VERSION ""

NS_ :

BS_:

BU_: LDCMC LDCMD LDCMF LDCME CSDB CSDA HCM TSTR LDCMA LDCMB

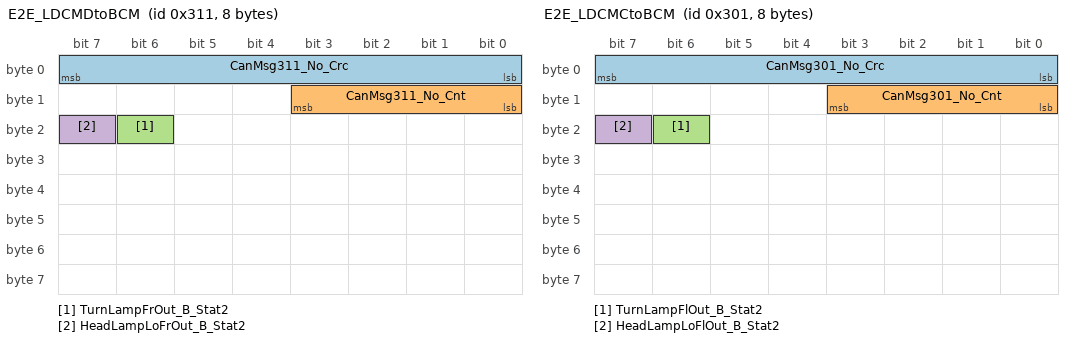
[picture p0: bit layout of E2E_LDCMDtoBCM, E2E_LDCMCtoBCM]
BO_ 785 E2E_LDCMDtoBCM: 8 LDCMD
 SG_ CanMsg311_No_Crc : 7|8@0+ (1,0) [0|255] "Unitless"  HCM
 SG_ CanMsg311_No_Cnt : 11|4@0+ (1,0) [0|15] "Unitless"  HCM
 SG_ TurnLampFrOut_B_Stat2 : 22|1@0+ (1,0) [0|1] ""  HCM
 SG_ HeadLampLoFrOut_B_Stat2 : 23|1@0+ (1,0) [0|1] "SED"  HCM

BO_ 769 E2E_LDCMCtoBCM: 8 LDCMC
 SG_ CanMsg301_No_Crc : 7|8@0+ (1,0) [0|255] "Unitless"  HCM
 SG_ CanMsg301_No_Cnt : 11|4@0+ (1,0) [0|15] "Unitless"  HCM
 SG_ TurnLampFlOut_B_Stat2 : 22|1@0+ (1,0) [0|1] ""  HCM
 SG_ HeadLampLoFlOut_B_Stat2 : 23|1@0+ (1,0) [0|1] "SED"  HCM

BO_ 125 HlStatFR2: 7 LDCMD
 SG_ LDM_HbFdbckRght_B_Stat2 : 10|1@0+ (1,0) [0|1] ""  HCM
 SG_ HlLoFrOnfdbck_B_Stat2 : 8|1@0+ (1,0) [0|1] "SED"  HCM
 SG_ Hlr_Temp_Stat2 : 4|1@0+ (1,0) [0|1] ""  HCM
 SG_ Mdule2RightHl_side_Stat : 3|2@0+ (1,0) [0|3] ""  HCM
 SG_ Mdule2RightHl_Com_Stat : 5|1@0+ (1,0) [0|1] ""  HCM
 SG_ Mdule2Right_MPwr_B_Stat : 6|1@0+ (1,0) [0|1] ""  HCM
 SG_ Mdule2Right_LB_Pwr_B_Stat : 7|1@0+ (1,0) [0|1] ""  HCM
 SG_ Hlr_SM_Stat2 : 13|1@0+ (1,0) [0|1] ""  HCM
 SG_ Hlr_SBL_Stat2 : 14|1@0+ (1,0) [0|1] ""  HCM
 SG_ Hlr_Pixel_Stat2 : 12|1@0+ (1,0) [0|1] ""  HCM
 SG_ Hlr_Fan_B_Stat2 : 15|1@0+ (1,0) [0|1] ""  HCM
 SG_ Hlr_DRL_POS_Stat2 : 11|1@0+ (1,0) [0|1] ""  HCM
 SG_ Hlr_LvlMotor_Temp_Stat2 : 23|2@0+ (1,0) [0|3] ""  HCM
 SG_ HeadLghtLvlRght_D_Stat2 : 21|3@0+ (1,0) [0|7] ""  HCM
 SG_ HeadLghtLvlRght_No_Stat2 : 29|12@0+ (1,0) [0|4095] "1/2 step"  HCM
 SG_ Mdule2RightFail_B_Stat : 1|1@0+ (1,0) [0|1] ""  HCM
 SG_ Mdule2RightConfg_B_Stat : 0|1@0+ (1,0) [0|1] ""  HCM

BO_ 124 HlStatFL2: 8 LDCMC
 SG_ LDM_HbFdbckLeft_B_Stat2 : 10|1@0+ (1,0) [0|1] ""  HCM
 SG_ HlLoFlOnfdbck_B_Stat2 : 8|1@0+ (1,0) [0|1] "SED"  HCM
 SG_ HeadLghtLvlLeft_No_Stat2 : 29|12@0+ (1,0) [0|4095] "1/2 step"  HCM
 SG_ Hll_Temp_Stat2 : 4|1@0+ (1,0) [0|1] ""  HCM
 SG_ Mdule2LeftHl_side_Stat : 3|2@0+ (1,0) [0|3] ""  HCM
 SG_ Mdule2LeftHl_Com_Stat : 5|1@0+ (1,0) [0|1] ""  HCM
 SG_ Mdule2Left_MPwr_B_Stat : 6|1@0+ (1,0) [0|1] ""  HCM
 SG_ Mdule2Left_LB_Pwr_B_Stat : 7|1@0+ (1,0) [0|1] ""  HCM
 SG_ Hll_SM_Stat2 : 13|1@0+ (1,0) [0|1] ""  HCM
 SG_ Hll_SBL_Stat2 : 14|1@0+ (1,0) [0|1] ""  HCM
 SG_ Hll_Pixel_Stat2 : 12|1@0+ (1,0) [0|1] ""  HCM
 SG_ Hll_Fan_B_Stat2 : 15|1@0+ (1,0) [0|1] ""  HCM
 SG_ Hll_DRL_POS_Stat2 : 11|1@0+ (1,0) [0|1] ""  HCM
 SG_ Hll_LvlMotor_Temp_Stat2 : 23|2@0+ (1,0) [0|3] ""  HCM
 SG_ HeadLghtLvlLeft_D_Stat2 : 21|3@0+ (1,0) [0|7] ""  HCM
 SG_ Mdule2LeftFail_B_Stat : 1|1@0+ (1,0) [0|1] ""  HCM
 SG_ Mdule2LeftConfg_B_Stat : 0|1@0+ (1,0) [0|1] ""  HCM

BO_ 1555 XCP_TSTRtoLDCMD: 64 TSTR
 SG_ XCP_TSTRtoLDCMD : 7|64@0+ (1,0) [0|1.84467E+019] "unitless"  LDCMD

BO_ 1554 XCP_TSTRtoLDCMC: 64 TSTR
 SG_ XCP_TSTRtoLDCMC : 7|64@0+ (1,0) [0|1.84467E+019] "unitless"  LDCMC

BO_ 1539 XCP_LDCMDtoTSTR: 64 LDCMD
 SG_ XCP_LDCMDtoTSTR : 7|64@0+ (1,0) [0|1.84467E+019] "unitless"  TSTR

BO_ 1538 XCP_LDCMCtoTSTR: 64 LDCMC
 SG_ XCP_LDCMCtoTSTR : 7|64@0+ (1,0) [0|1.84467E+019] "unitless"  TSTR

BO_ 2612224122 PARSEDPushLDCMDtoGWM_ECG: 64 LDCMD
 SG_ PARSEDPushLDCMDtoGWM_ECG : 7|29@0+ (1,0) [0|536870911] "unitless"  HCM

BO_ 2612224125 PARSEDPushLDCMCtoGWM_ECG: 64 LDCMC
 SG_ PARSEDPushLDCMCtoGWM_ECG : 7|29@0+ (1,0) [0|536870911] "unitless"  HCM

BO_ 2612127960 PARSEDPushFcGWM_ECGtoLDCMD: 64 HCM
 SG_ PARSEDPushFcGWM_ECGtoLDCMD : 7|29@0+ (1,0) [0|536870911] "unitless"  LDCMD

BO_ 2612131032 PARSEDPushFcGWM_ECGtoLDCMC: 64 HCM
 SG_ PARSEDPushFcGWM_ECGtoLDCMC : 7|29@0+ (1,0) [0|536870911] "unitless"  LDCMC

BO_ 2611175546 PARSEDPhysLDCMDtoGWM_ECG: 64 LDCMD
 SG_ PARSEDPhysLDCMDtoGWM_ECG : 7|29@0+ (1,0) [0|536870911] "unitless"  HCM

BO_ 2611175549 PARSEDPhysLDCMCtoGWM_ECG: 64 LDCMC
 SG_ PARSEDPhysLDCMCtoGWM_ECG : 7|29@0+ (1,0) [0|536870911] "unitless"  HCM

BO_ 2611079384 PARSEDPhysGWM_ECGtoLDCMD: 64 HCM
 SG_ PARSEDPhysGWM_ECGtoLDCMD : 7|29@0+ (1,0) [0|536870911] "unitless"  LDCMD

BO_ 2611082456 PARSEDPhysGWM_ECGtoLDCMC: 64 HCM
 SG_ PARSEDPhysGWM_ECGtoLDCMC : 7|29@0+ (1,0) [0|536870911] "unitless"  LDCMC

BO_ 2610126970 OTAPhysLDCMDtoGWM_ECG: 64 LDCMD
 SG_ OTAPhysLDCMDtoGWM_ECG : 7|29@0+ (1,0) [0|536870911] "unitless"  HCM

BO_ 2610126973 OTAPhysLDCMCtoGWM_ECG: 64 LDCMC
 SG_ OTAPhysLDCMCtoGWM_ECG : 7|29@0+ (1,0) [0|536870911] "unitless"  HCM

BO_ 2610030808 OTAPhysGWM_ECGtoLDCMD: 64 HCM
 SG_ OTAPhysGWM_ECGtoLDCMD : 7|29@0+ (1,0) [0|536870911] "unitless"  LDCMD

BO_ 2610033880 OTAPhysGWM_ECGtoLDCMC: 64 HCM
 SG_ OTAPhysGWM_ECGtoLDCMC : 7|29@0+ (1,0) [0|536870911] "unitless"  LDCMC

BO_ 1758 TesterPhysicalResLDCMD: 64 LDCMD
 SG_ TesterPhysicalResLDCMD : 7|64@0+ (1,0) [0|1.84467E+019] "unitless"  HCM

BO_ 1759 TesterPhysicalResLDCMC: 64 LDCMC
 SG_ TesterPhysicalResLDCMC : 7|64@0+ (1,0) [0|1.84467E+019] "unitless"  HCM

BO_ 1750 TesterPhysicalReqLDCMD: 64 HCM
 SG_ TesterPhysicalReqLDCMD : 7|64@0+ (1,0) [0|1.84467E+019] "unitless"  LDCMD

BO_ 1751 TesterPhysicalReqLDCMC: 64 HCM
 SG_ TesterPhysicalReqLDCMC : 7|64@0+ (1,0) [0|1.84467E+019] "unitless"  LDCMC

BO_ 123 RlStatRR1: 7 LDCMF
 SG_ TailLghtAnmtnRight_D_Stat : 2|4@0+ (1,0) [0|15] "SED"  HCM

BO_ 122 RlStatRL1: 8 LDCME
 SG_ TailLghtAnmtnLeft_D_Stat : 2|4@0+ (1,0) [0|15] "SED"  HCM

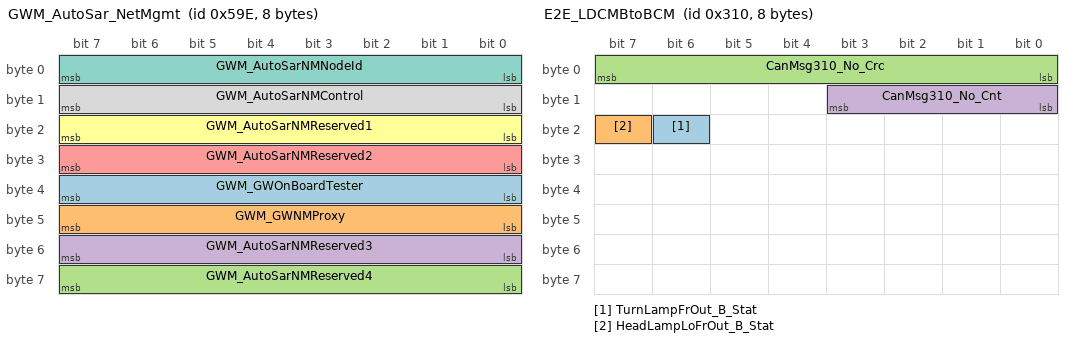
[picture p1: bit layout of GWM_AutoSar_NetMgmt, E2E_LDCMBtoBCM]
BO_ 1438 GWM_AutoSar_NetMgmt: 8 HCM
 SG_ GWM_GWOnBoardTester : 39|8@0+ (1,0) [0|255] "unitless"  LDCMC,LDCMD,LDCMF,LDCME,LDCMB,LDCMA
 SG_ GWM_GWNMProxy : 47|8@0+ (1,0) [0|255] "unitless"  LDCMC,LDCMD,LDCMF,LDCME,LDCMB,LDCMA
 SG_ GWM_AutoSarNMReserved4 : 63|8@0+ (1,0) [0|255] "unitless"  LDCMC,LDCMD,LDCMF,LDCME,LDCMB,LDCMA
 SG_ GWM_AutoSarNMReserved3 : 55|8@0+ (1,0) [0|255] "unitless"  LDCMC,LDCMD,LDCMF,LDCME,LDCMB,LDCMA
 SG_ GWM_AutoSarNMReserved2 : 31|8@0+ (1,0) [0|255] "unitless"  LDCMC,LDCMD,LDCMF,LDCME,LDCMB,LDCMA
 SG_ GWM_AutoSarNMReserved1 : 23|8@0+ (1,0) [0|255] "unitless"  LDCMC,LDCMD,LDCMF,LDCME,LDCMB,LDCMA
 SG_ GWM_AutoSarNMNodeId : 7|8@0+ (1,0) [0|255] "unitless"  LDCMC,LDCMD,LDCMF,LDCME,LDCMB,LDCMA
 SG_ GWM_AutoSarNMControl : 15|8@0+ (1,0) [0|255] "unitless"  LDCMC,LDCMD,LDCMF,LDCME,LDCMB,LDCMA

BO_ 102 HighBeamMaster: 64 HCM
 SG_ Hbm6TrnstnRight_An_Rq : 419|4@0+ (0.2,0) [0|3] "degrees"  LDCMC,LDCMD,LDCMB,LDCMA
 SG_ Hbm6TrnstnLeft_An_Rq : 423|4@0+ (0.2,0) [0|3] "degrees"  LDCMC,LDCMD,LDCMB,LDCMA
 SG_ Hbm6RightLghtRigh_An_Rq : 432|9@0+ (0.1,-25.6) [-25.6|25.5] "degrees"  LDCMD,LDCMB
 SG_ Hbm6RightLghtLeft_An_Rq : 400|9@0+ (0.1,-25.6) [-25.6|25.5] "degrees"  LDCMD,LDCMB
 SG_ Hbm6Ramping_T_Rq : 387|4@0+ (0.2,0) [0|3] "second"  LDCMC,LDCMD,LDCMB,LDCMA
 SG_ Hbm6LeftLghtRight_An_Rq : 431|9@0+ (0.1,-25.6) [-25.6|25.5] "degrees"  LDCMC,LDCMA
 SG_ Hbm6LeftLghtLeft_An_Rq : 399|9@0+ (0.1,-25.6) [-25.6|25.5] "degrees"  LDCMC,LDCMA
 SG_ Hbm6BrdrTop_An_Rq : 438|6@0+ (0.1,-5) [-5|1.3] "degrees"  LDCMC,LDCMD,LDCMB,LDCMA
 SG_ Hbm6BrdrBottom_An_Rq : 406|6@0+ (0.1,-5) [-5|1.3] "degrees"  LDCMC,LDCMD,LDCMB,LDCMA
 SG_ Hbm5TrnstnRight_An_Rq : 355|4@0+ (0.2,0) [0|3] "degrees"  LDCMC,LDCMD,LDCMB,LDCMA
 SG_ Hbm5TrnstnLeft_An_Rq : 359|4@0+ (0.2,0) [0|3] "degrees"  LDCMC,LDCMD,LDCMB,LDCMA
 SG_ Hbm5RightLghtRigh_An_Rq : 368|9@0+ (0.1,-25.6) [-25.6|25.5] "degrees"  LDCMD,LDCMB
 SG_ Hbm5RightLghtLeft_An_Rq : 336|9@0+ (0.1,-25.6) [-25.6|25.5] "degrees"  LDCMD,LDCMB
 SG_ Hbm5Ramping_T_Rq : 323|4@0+ (0.2,0) [0|3] "second"  LDCMC,LDCMD,LDCMB,LDCMA
 SG_ Hbm5LeftLghtRight_An_Rq : 367|9@0+ (0.1,-25.6) [-25.6|25.5] "degrees"  LDCMC,LDCMA
 SG_ Hbm5LeftLghtLeft_An_Rq : 335|9@0+ (0.1,-25.6) [-25.6|25.5] "degrees"  LDCMC,LDCMA
 SG_ Hbm5BrdrTop_An_Rq : 374|6@0+ (0.1,-5) [-5|1.3] "degrees"  LDCMC,LDCMD,LDCMB,LDCMA
 SG_ Hbm5BrdrBottom_An_Rq : 342|6@0+ (0.1,-5) [-5|1.3] "degrees"  LDCMC,LDCMD,LDCMB,LDCMA
 SG_ Hbm4TrnstnRight_An_Rq : 291|4@0+ (0.2,0) [0|3] "degrees"  LDCMC,LDCMD,LDCMB,LDCMA
 SG_ Hbm4TrnstnLeft_An_Rq : 295|4@0+ (0.2,0) [0|3] "degrees"  LDCMC,LDCMD,LDCMB,LDCMA
 SG_ Hbm4RightLghtRigh_An_Rq : 304|9@0+ (0.1,-25.6) [-25.6|25.5] "degrees"  LDCMD,LDCMB
 SG_ Hbm4RightLghtLeft_An_Rq : 272|9@0+ (0.1,-25.6) [-25.6|25.5] "degrees"  LDCMD,LDCMB
 SG_ Hbm4Ramping_T_Rq : 259|4@0+ (0.2,0) [0|3] "second"  LDCMC,LDCMD,LDCMB,LDCMA
 SG_ Hbm4LeftLghtRight_An_Rq : 303|9@0+ (0.1,-25.6) [-25.6|25.5] "degrees"  LDCMC,LDCMA
 SG_ Hbm4LeftLghtLeft_An_Rq : 271|9@0+ (0.1,-25.6) [-25.6|25.5] "degrees"  LDCMC,LDCMA
 SG_ Hbm4BrdrTop_An_Rq : 310|6@0+ (0.1,-5) [-5|1.3] "degrees"  LDCMC,LDCMD,LDCMB,LDCMA
 SG_ Hbm4BrdrBottom_An_Rq : 278|6@0+ (0.1,-5) [-5|1.3] "degrees"  LDCMC,LDCMD,LDCMB,LDCMA
 SG_ Hbm3TrnstnRight_An_Rq : 227|4@0+ (0.2,0) [0|3] "degrees"  LDCMC,LDCMD,LDCMB,LDCMA
 SG_ Hbm3TrnstnLeft_An_Rq : 231|4@0+ (0.2,0) [0|3] "degrees"  LDCMC,LDCMD,LDCMB,LDCMA
 SG_ Hbm3RightLghtRigh_An_Rq : 240|9@0+ (0.1,-25.6) [-25.6|25.5] "degrees"  LDCMD,LDCMB
 SG_ Hbm3RightLghtLeft_An_Rq : 208|9@0+ (0.1,-25.6) [-25.6|25.5] "degrees"  LDCMD,LDCMB
 SG_ Hbm3Ramping_T_Rq : 195|4@0+ (0.2,0) [0|3] "second"  LDCMC,LDCMD,LDCMB,LDCMA
 SG_ Hbm3LeftLghtRight_An_Rq : 239|9@0+ (0.1,-25.6) [-25.6|25.5] "degrees"  LDCMC,LDCMA
 SG_ Hbm3BrdrTop_An_Rq : 246|6@0+ (0.1,-5) [-5|1.3] "degrees"  LDCMC,LDCMD,LDCMB,LDCMA
 SG_ Hbm3BrdrBottom_An_Rq : 214|6@0+ (0.1,-5) [-5|1.3] "degrees"  LDCMC,LDCMD,LDCMB,LDCMA
 SG_ Hbm2BrdrBottom_An_Rq : 150|6@0+ (0.1,-5) [-5|1.3] "degrees"  LDCMC,LDCMD,LDCMB,LDCMA
 SG_ Hbm1BrdrBottom_An_Rq : 86|6@0+ (0.1,-5) [-5|1.3] "degrees"  LDCMC,LDCMD,LDCMB,LDCMA
 SG_ Hbm2BrdrTop_An_Rq : 182|6@0+ (0.1,-5) [-5|1.3] "degrees"  LDCMC,LDCMD,LDCMB,LDCMA
 SG_ Hbm1BrdrTop_An_Rq : 118|6@0+ (0.1,-5) [-5|1.3] "degrees"  LDCMC,LDCMD,LDCMB,LDCMA
 SG_ Hbm2TrnstnRight_An_Rq : 163|4@0+ (0.2,0) [0|3] "degrees"  LDCMC,LDCMD,LDCMB,LDCMA
 SG_ Hbm1TrnstnRight_An_Rq : 99|4@0+ (0.2,0) [0|3] "degrees"  LDCMC,LDCMD,LDCMB,LDCMA
 SG_ Hbm2RightLghtRigh_An_Rq : 176|9@0+ (0.1,-25.6) [-25.6|25.5] "degrees"  LDCMD,LDCMB
 SG_ Hbm1RightLghtRigh_An_Rq : 112|9@0+ (0.1,-25.6) [-25.6|25.5] "degrees"  LDCMD,LDCMB
 SG_ Hbm2LeftLghtRight_An_Rq : 175|9@0+ (0.1,-25.6) [-25.6|25.5] "degrees"  LDCMC,LDCMA
 SG_ Hbm1LeftLghtRight_An_Rq : 111|9@0+ (0.1,-25.6) [-25.6|25.5] "degrees"  LDCMC,LDCMA
 SG_ Hbm2TrnstnLeft_An_Rq : 167|4@0+ (0.2,0) [0|3] "degrees"  LDCMC,LDCMD,LDCMB,LDCMA
 SG_ Hbm1TrnstnLeft_An_Rq : 103|4@0+ (0.2,0) [0|3] "degrees"  LDCMC,LDCMD,LDCMB,LDCMA
 SG_ Hbm2RightLghtLeft_An_Rq : 144|9@0+ (0.1,-25.6) [-25.6|25.5] "degrees"  LDCMD,LDCMB
 SG_ Hbm1RightLghtLeft_An_Rq : 80|9@0+ (0.1,-25.6) [-25.6|25.5] "degrees"  LDCMD,LDCMB
 SG_ Hbm3LeftLghtLeft_An_Rq : 207|9@0+ (0.1,-25.6) [-25.6|25.5] "degrees"  LDCMC,LDCMA
 SG_ Hbm2LeftLghtLeft_An_Rq : 143|9@0+ (0.1,-25.6) [-25.6|25.5] "degrees"  LDCMC,LDCMA
 SG_ Hbm1LeftLghtLeft_An_Rq : 79|9@0+ (0.1,-25.6) [-25.6|25.5] "degrees"  LDCMC,LDCMA
 SG_ Hbm2Ramping_T_Rq : 131|4@0+ (0.2,0) [0|3] "second"  LDCMC,LDCMD,LDCMB,LDCMA
 SG_ Hbm1Ramping_T_Rq : 67|4@0+ (0.2,0) [0|3] "second"  LDCMC,LDCMD,LDCMB,LDCMA
 SG_ Hbm6Mde_D_Rq : 391|4@0+ (1,0) [0|15] "SED"  LDCMC,LDCMD,LDCMB,LDCMA
 SG_ Hbm5Mde_D_Rq : 327|4@0+ (1,0) [0|15] "SED"  LDCMC,LDCMD,LDCMB,LDCMA
 SG_ Hbm4Mde_D_Rq : 263|4@0+ (1,0) [0|15] "SED"  LDCMC,LDCMD,LDCMB,LDCMA
 SG_ Hbm3Mde_D_Rq : 199|4@0+ (1,0) [0|15] "SED"  LDCMC,LDCMD,LDCMB,LDCMA
 SG_ Hbm2Mde_D_Rq : 135|4@0+ (1,0) [0|15] "SED"  LDCMC,LDCMD,LDCMB,LDCMA
 SG_ Hbm1Mde_D_Rq : 71|4@0+ (1,0) [0|15] "SED"  LDCMC,LDCMD,LDCMB,LDCMA
 SG_ HeadLghtHi_T_Rq : 4|4@0+ (0.2,0) [0|3] "second"  LDCMC,LDCMD,LDCMB,LDCMA
 SG_ HeadLghtHi_D_Rq : 7|3@0+ (1,0) [0|7] "SED"  LDCMC,LDCMD,LDCMB,LDCMA

BO_ 784 E2E_LDCMBtoBCM: 8 LDCMB
 SG_ TurnLampFrOut_B_Stat : 22|1@0+ (1,0) [0|1] ""  HCM
 SG_ HeadLampLoFrOut_B_Stat : 23|1@0+ (1,0) [0|1] "SED"  HCM
 SG_ CanMsg310_No_Crc : 7|8@0+ (1,0) [0|255] "Unitless"  HCM
 SG_ CanMsg310_No_Cnt : 11|4@0+ (1,0) [0|15] "Unitless"  HCM

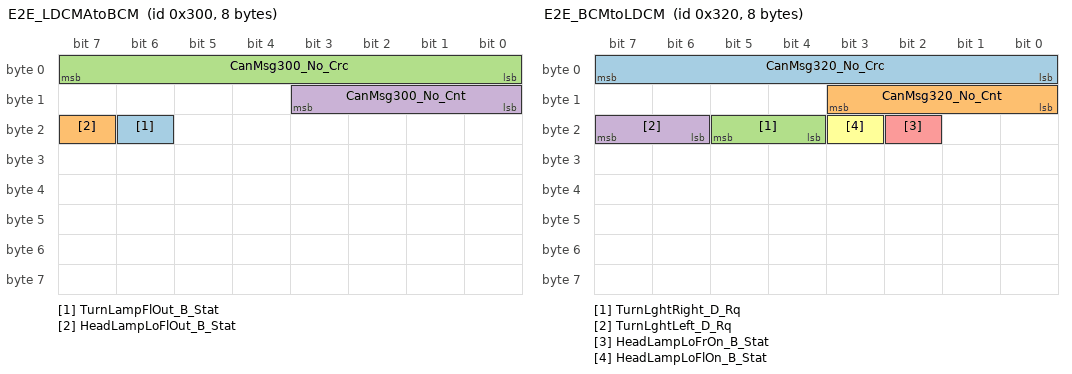
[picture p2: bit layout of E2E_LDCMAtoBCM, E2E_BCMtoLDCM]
BO_ 768 E2E_LDCMAtoBCM: 8 LDCMA
 SG_ TurnLampFlOut_B_Stat : 22|1@0+ (1,0) [0|1] ""  HCM
 SG_ HeadLampLoFlOut_B_Stat : 23|1@0+ (1,0) [0|1] "SED"  HCM
 SG_ CanMsg300_No_Crc : 7|8@0+ (1,0) [0|255] "Unitless"  HCM
 SG_ CanMsg300_No_Cnt : 11|4@0+ (1,0) [0|15] "Unitless"  HCM

BO_ 1553 XCP_TSTRtoLDCMB: 64 TSTR
 SG_ XCP_TSTRtoLDCMB : 7|64@0+ (1,0) [0|1.84467E+019] "unitless"  LDCMB

BO_ 1552 XCP_TSTRtoLDCMA: 64 TSTR
 SG_ XCP_TSTRtoLDCMA : 7|64@0+ (1,0) [0|1.84467E+019] "unitless"  LDCMA

BO_ 1537 XCP_LDCMBtoTSTR: 64 LDCMB
 SG_ XCP_LDCMBtoTSTR : 7|64@0+ (1,0) [0|1.84467E+019] "unitless"  TSTR

BO_ 1536 XCP_LDCMAtoTSTR: 64 LDCMA
 SG_ XCP_LDCMAtoTSTR : 7|64@0+ (1,0) [0|1.84467E+019] "unitless"  TSTR

BO_ 2612224078 PARSEDPushLDCMBtoGWM_ECG: 64 LDCMB
 SG_ PARSEDPushLDCMBtoGWM_ECG : 7|29@0+ (1,0) [0|536870911] "unitless"  HCM

BO_ 2612082904 PARSEDPushFcGWM_ECGtoLDCMB: 64 HCM
 SG_ PARSEDPushFcGWM_ECGtoLDCMB : 7|29@0+ (1,0) [0|536870911] "unitless"  LDCMB

BO_ 2611175502 PARSEDPhysLDCMBtoGWM_ECG: 64 LDCMB
 SG_ PARSEDPhysLDCMBtoGWM_ECG : 7|29@0+ (1,0) [0|536870911] "unitless"  HCM

BO_ 2611034328 PARSEDPhysGWM_ECGtoLDCMB: 64 HCM
 SG_ PARSEDPhysGWM_ECGtoLDCMB : 7|29@0+ (1,0) [0|536870911] "unitless"  LDCMB

BO_ 2610126926 OTAPhysLDCMBtoGWM_ECG: 64 LDCMB
 SG_ OTAPhysLDCMBtoGWM_ECG : 7|29@0+ (1,0) [0|536870911] "unitless"  HCM

BO_ 2609985752 OTAPhysGWM_ECGtoLDCMB: 64 HCM
 SG_ OTAPhysGWM_ECGtoLDCMB : 7|29@0+ (1,0) [0|536870911] "unitless"  LDCMB

BO_ 2612224079 PARSEDPushLDCMAtoGWM_ECG: 64 LDCMA
 SG_ PARSEDPushLDCMAtoGWM_ECG : 7|29@0+ (1,0) [0|536870911] "unitless"  HCM

BO_ 1798 TesterPhysicalReqDev: 64 TSTR
 SG_ TesterPhysicalReqDev : 7|64@0+ (1,0) [0|1.84467E+019] "unitless"  CSDB,CSDA

BO_ 1806 TesterPhysicalResDev: 64 CSDA
 SG_ TesterPhysicalResDev : 7|64@0+ (1,0) [0|1.84467E+019] "unitless"  TSTR

BO_ 800 E2E_BCMtoLDCM: 8 HCM
 SG_ CanMsg320_No_Crc : 7|8@0+ (1,0) [0|255] "Unitless"  LDCMC,LDCMD,LDCMB,LDCMA,LDCMF,LDCME
 SG_ CanMsg320_No_Cnt : 11|4@0+ (1,0) [0|15] "Unitless"  LDCMC,LDCMD,LDCMB,LDCMA,LDCMF,LDCME
 SG_ TurnLghtRight_D_Rq : 21|2@0+ (1,0) [0|3] "SED"  LDCMC,LDCMD,LDCMF,LDCME,LDCMA,LDCMB
 SG_ TurnLghtLeft_D_Rq : 23|2@0+ (1,0) [0|3] "SED"  LDCMC,LDCMD,LDCMF,LDCME,LDCMB,LDCMA
 SG_ HeadLampLoFrOn_B_Stat : 18|1@0+ (1,0) [0|1] "SED"  LDCMC,LDCMD,LDCMF,LDCME,LDCMA,LDCMB
 SG_ HeadLampLoFlOn_B_Stat : 19|1@0+ (1,0) [0|1] "SED"  LDCMC,LDCMD,LDCMF,LDCME,LDCMB,LDCMA

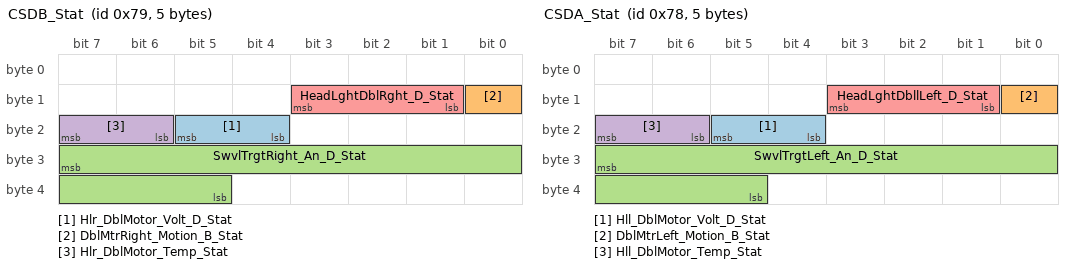
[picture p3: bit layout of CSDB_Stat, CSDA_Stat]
BO_ 121 CSDB_Stat: 5 CSDB
 SG_ Hlr_DblMotor_Volt_D_Stat : 21|2@0+ (1,0) [0|3] ""  HCM
 SG_ DblMtrRight_Motion_B_Stat : 8|1@0+ (1,0) [0|1] ""  HCM
 SG_ SwvlTrgtRight_An_D_Stat : 31|11@0+ (0.04,-35) [-35|46.88] "Degrees"  HCM
 SG_ Hlr_DblMotor_Temp_Stat : 23|2@0+ (1,0) [0|3] ""  HCM
 SG_ HeadLghtDblRght_D_Stat : 11|3@0+ (1,0) [0|7] ""  HCM

BO_ 120 CSDA_Stat: 5 CSDA
 SG_ Hll_DblMotor_Volt_D_Stat : 21|2@0+ (1,0) [0|3] ""  HCM
 SG_ DblMtrLeft_Motion_B_Stat : 8|1@0+ (1,0) [0|1] ""  HCM
 SG_ SwvlTrgtLeft_An_D_Stat : 31|11@0+ (0.04,-35) [-35|46.88] "Degrees"  HCM
 SG_ Hll_DblMotor_Temp_Stat : 23|2@0+ (1,0) [0|3] ""  HCM
 SG_ HeadLghtDbllLeft_D_Stat : 11|3@0+ (1,0) [0|7] ""  HCM

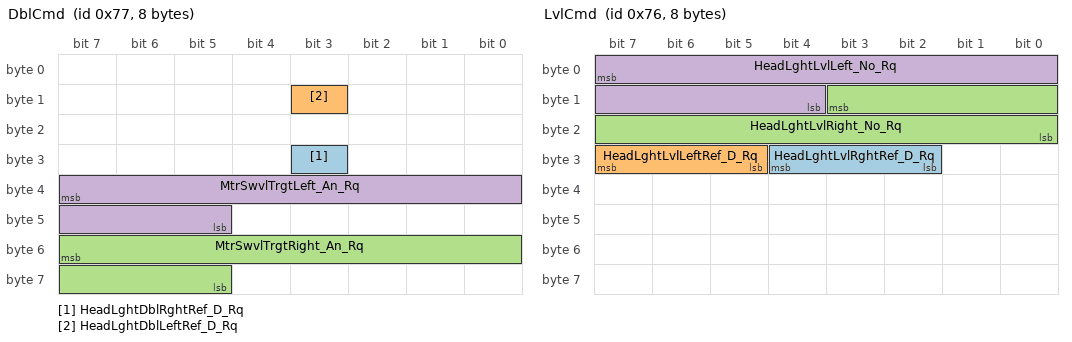
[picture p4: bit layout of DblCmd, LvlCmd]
BO_ 119 DblCmd: 8 HCM
 SG_ HeadLghtDblRghtRef_D_Rq : 27|1@0+ (1,0) [0|1] ""  CSDB
 SG_ HeadLghtDblLeftRef_D_Rq : 11|1@0+ (1,0) [0|1] ""  CSDA
 SG_ MtrSwvlTrgtRight_An_Rq : 55|11@0+ (0.04,-35) [-35|46.88] "Degrees"  CSDB
 SG_ MtrSwvlTrgtLeft_An_Rq : 39|11@0+ (0.04,-35) [-35|46.88] "Degrees"  CSDA

BO_ 1805 TesterPhysicalResCDSB: 64 CSDB
 SG_ TesterPhysicalResCDSB : 7|64@0+ (1,0) [0|1.84467E+019] "unitless"  TSTR

BO_ 1797 TesterPhysicalReqCDSB: 64 TSTR
 SG_ TesterPhysicalReqCDSB : 7|64@0+ (1,0) [0|1.84467E+019] "unitless"  CSDB

BO_ 1796 TesterPhysicalReqCDSA: 64 TSTR
 SG_ TesterPhysicalReqCDSA : 7|64@0+ (1,0) [0|1.84467E+019] "unitless"  CSDA

BO_ 1804 TesterPhysicalResCDSA: 64 CSDA
 SG_ TesterPhysicalResCDSA : 7|64@0+ (1,0) [0|1.84467E+019] "unitless"  TSTR

BO_ 2611035352 PARSEDPhysGWM_ECGtoLDCMA: 64 HCM
 SG_ PARSEDPhysGWM_ECGtoLDCMA : 7|29@0+ (1,0) [0|536870911] "unitless"  LDCMA

BO_ 2612083928 PARSEDPushFcGWM_ECGtoLDCMA: 64 HCM
 SG_ PARSEDPushFcGWM_ECGtoLDCMA : 7|29@0+ (1,0) [0|536870911] "unitless"  LDCMA

BO_ 2611175503 PARSEDPhysLDCMAtoGWM_ECG: 64 LDCMA
 SG_ PARSEDPhysLDCMAtoGWM_ECG : 7|29@0+ (1,0) [0|536870911] "unitless"  HCM

BO_ 2612002008 PARSEDFuncGWM_ECG_HCM: 64 HCM
 SG_ PARSEDFuncGWM_ECG : 7|29@0+ (1,0) [0|536870911] "unitless"  LDCMC,LDCMD,LDCMB,LDCMA

BO_ 2610126927 OTAPhysLDCMAtoGWM_ECG: 64 LDCMA
 SG_ OTAPhysLDCMAtoGWM_ECG : 7|29@0+ (1,0) [0|536870911] "unitless"  HCM

BO_ 2609986776 OTAPhysGWM_ECGtoLDCMA: 64 HCM
 SG_ OTAPhysGWM_ECGtoLDCMA : 7|29@0+ (1,0) [0|536870911] "unitless"  LDCMA

BO_ 2610953432 OTAFuncGWM_ECG_HCM: 64 HCM
 SG_ OTAFuncGWM_ECG : 7|29@0+ (1,0) [0|536870911] "unitless"  LDCMC,LDCMD,LDCMA,LDCMB

BO_ 80 BaseFeaturesActvRq: 7 HCM
 SG_ ExtLghtAnmtn_D_Rq : 7|4@0+ (1,0) [0|15] "SED"  LDCMC,LDCMD,LDCMF,LDCME,LDCMB,LDCMA
 SG_ HeadLghtSwtch_D_Stat : 2|2@0+ (1,0) [0|3] "SED"  LDCMC,LDCMD,LDCMB,LDCMA
 SG_ DrlPos4_Actv_Rf_Rq : 33|2@0+ (1,0) [0|3] " "  LDCMC,LDCMD,LDCMB,LDCMA
 SG_ DrlPos4_Actv_Lf_Rq : 35|2@0+ (1,0) [0|3] " "  LDCMC,LDCMD,LDCMB,LDCMA
 SG_ DrlPos3_Actv_Rf_Rq : 37|2@0+ (1,0) [0|3] " "  LDCMC,LDCMD,LDCMB,LDCMA
 SG_ DrlPos3_Actv_Lf_Rq : 39|2@0+ (1,0) [0|3] ""  LDCMC,LDCMD,LDCMB,LDCMA
 SG_ ExtLghtFront_D_RqBody : 25|2@0+ (1,0) [0|3] "SED"  LDCMC,LDCMD,LDCMB,LDCMA
 SG_ Front_Fog_Actv_Rq : 26|1@0+ (1,0) [0|1] " SED"  LDCMC,LDCMD,LDCMA,LDCMB
 SG_ WfSubstate_D_Stat : 29|3@0+ (1,0) [0|7] ""  LDCMC,LDCMD,LDCME,LDCMF,LDCMB,LDCMA
 SG_ WfSuperstate_D_Stat : 31|2@0+ (1,0) [0|3] ""  LDCMC,LDCMD,LDCME,LDCMF,LDCMB,LDCMA
 SG_ Drl_Pos_Actv_Fade_Rf_Rq : 19|4@0+ (200,0) [0|3000] "ms"  LDCMD,LDCMB
 SG_ SideMarker_Actv_Rq : 0|1@0+ (1,0) [0|1] ""  LDCMC,LDCMD,LDCMB,LDCMA
 SG_ Drl_Pos_Actv_Fade_Lf_Rq : 23|4@0+ (200,0) [0|3000] "ms"  LDCMC,LDCMA
 SG_ DrlPos2_Actv_Rf_Rq : 9|2@0+ (1,0) [0|3] " "  LDCMC,LDCMD,LDCMA,LDCMB
 SG_ DrlPos1_Actv_Rf_Rq : 13|2@0+ (1,0) [0|3] " "  LDCMC,LDCMD,LDCMA,LDCMB
 SG_ DrlPos2_Actv_Lf_Rq : 11|2@0+ (1,0) [0|3] " "  LDCMC,LDCMD,LDCMB,LDCMA
 SG_ DrlPos1_Actv_Lf_Rq : 15|2@0+ (1,0) [0|3] " "  LDCMC,LDCMD,LDCMB,LDCMA

BO_ 2015 TesterFunctionalReq_HCM: 64 TSTR
 SG_ TesterFunctionalReq : 7|64@0+ (1,0) [0|1.84467E+019] "unitless"  LDCMC,LDCMD,LDCMA,LDCMB

BO_ 1791 TesterPhysicalResLDCMB: 64 LDCMB
 SG_ TesterPhysicalResLDCMB : 7|64@0+ (1,0) [0|1.84467E+019] "unitless"  TSTR,HCM

BO_ 1790 TesterPhysicalResLDCMA: 64 LDCMA
 SG_ TesterPhysicalResLDCMA : 7|64@0+ (1,0) [0|1.84467E+019] "unitless"  TSTR,HCM

BO_ 1783 TesterPhysicalReqLDCMB: 64 TSTR
 SG_ TesterPhysicalReqLDCMB : 7|64@0+ (1,0) [0|1.84467E+019] "unitless"  LDCMB

BO_ 1782 TesterPhysicalReqLDCMA: 64 TSTR
 SG_ TesterPhysicalReqLDCMA : 7|64@0+ (1,0) [0|1.84467E+019] "unitless"  LDCMA

BO_ 1823 TesterPhysicalResLDCMF: 64 LDCMF
 SG_ TesterPhysicalResLDCMF : 7|64@0+ (1,0) [0|1.84467E+019] "unitless"  TSTR,HCM

BO_ 1822 TesterPhysicalResLDCME: 64 LDCME
 SG_ TesterPhysicalResLDCME : 7|64@0+ (1,0) [0|1.84467E+019] "unitless"  TSTR,HCM

BO_ 1815 TesterPhysicalReqLDCMF: 64 TSTR
 SG_ TesterPhysicalReqLDCMF : 7|64@0+ (1,0) [0|1.84467E+019] "unitless"  LDCMF

BO_ 1814 TesterPhysicalReqLDCME: 64 TSTR
 SG_ TesterPhysicalReqLDCME : 7|64@0+ (1,0) [0|1.84467E+019] "unitless"  LDCME

BO_ 117 HlStatFR1: 7 LDCMB
 SG_ LDM_HbFdbckRght_B_Stat : 10|1@0+ (1,0) [0|1] ""  HCM
 SG_ HlLoFrOnfdbck_B_Stat : 8|1@0+ (1,0) [0|1] "SED"  HCM
 SG_ Hlr_Temp_Stat : 4|1@0+ (1,0) [0|1] ""  HCM
 SG_ Mdule1RightHl_side_Stat : 3|2@0+ (1,0) [0|3] ""  HCM
 SG_ Mdule1RightHl_Com_Stat : 5|1@0+ (1,0) [0|1] ""  HCM
 SG_ Mdule1Right_MPwr_B_Stat : 6|1@0+ (1,0) [0|1] ""  HCM
 SG_ Mdule1Right_LB_Pwr_B_Stat : 7|1@0+ (1,0) [0|1] ""  HCM
 SG_ Hlr_SM_Stat : 13|1@0+ (1,0) [0|1] ""  HCM
 SG_ Hlr_SBL_Stat : 14|1@0+ (1,0) [0|1] ""  HCM
 SG_ Hlr_Pixel_Stat : 12|1@0+ (1,0) [0|1] ""  HCM
 SG_ Hlr_Fan_B_Stat : 15|1@0+ (1,0) [0|1] ""  HCM
 SG_ Hlr_DRL_POS_Stat : 11|1@0+ (1,0) [0|1] ""  HCM
 SG_ Hlr_LvlMotor_Temp_Stat : 23|2@0+ (1,0) [0|3] ""  HCM
 SG_ HeadLghtLvlRght_D_Stat : 21|3@0+ (1,0) [0|7] ""  HCM
 SG_ HeadLghtLvlRght_No_Stat : 29|12@0+ (1,0) [0|4095] "1/2 step"  HCM
 SG_ Mdule1RightFail_B_Stat : 1|1@0+ (1,0) [0|1] ""  HCM
 SG_ Mdule1RightConfg_B_Stat : 0|1@0+ (1,0) [0|1] ""  HCM

BO_ 116 HlStatFL1: 8 LDCMA
 SG_ LDM_HbFdbckLeft_B_Stat : 10|1@0+ (1,0) [0|1] ""  HCM
 SG_ HlLoFlOnfdbck_B_Stat : 8|1@0+ (1,0) [0|1] "SED"  HCM
 SG_ HeadLghtLvlLeft_No_Stat : 29|12@0+ (1,0) [0|4095] "1/2 step"  HCM
 SG_ Hll_Temp_Stat : 4|1@0+ (1,0) [0|1] ""  HCM
 SG_ Mdule1LeftHl_side_Stat : 3|2@0+ (1,0) [0|3] ""  HCM
 SG_ Mdule1LeftHl_Com_Stat : 5|1@0+ (1,0) [0|1] ""  HCM
 SG_ Mdule1Left_MPwr_B_Stat : 6|1@0+ (1,0) [0|1] ""  HCM
 SG_ Mdule1Left_LB_Pwr_B_Stat : 7|1@0+ (1,0) [0|1] ""  HCM
 SG_ Hll_SM_Stat : 13|1@0+ (1,0) [0|1] ""  HCM
 SG_ Hll_SBL_Stat : 14|1@0+ (1,0) [0|1] ""  HCM
 SG_ Hll_Pixel_Stat : 12|1@0+ (1,0) [0|1] ""  HCM
 SG_ Hll_Fan_B_Stat : 15|1@0+ (1,0) [0|1] ""  HCM
 SG_ Hll_DRL_POS_Stat : 11|1@0+ (1,0) [0|1] ""  HCM
 SG_ Hll_LvlMotor_Temp_Stat : 23|2@0+ (1,0) [0|3] ""  HCM
 SG_ HeadLghtLvlLeft_D_Stat : 21|3@0+ (1,0) [0|7] ""  HCM
 SG_ Mdule1LeftFail_B_Stat : 1|1@0+ (1,0) [0|1] ""  HCM
 SG_ Mdule1LeftConfg_B_Stat : 0|1@0+ (1,0) [0|1] ""  HCM

BO_ 118 LvlCmd: 8 HCM
 SG_ HeadLghtLvlRghtRef_D_Rq : 28|3@0+ (1,0) [0|7] ""  LDCMD,LDCMB
 SG_ HeadLghtLvlLeftRef_D_Rq : 31|3@0+ (1,0) [0|7] ""  LDCMC,LDCMA
 SG_ HeadLghtLvlRight_No_Rq : 11|12@0+ (1,0) [0|4095] "1/2 step"  LDCMD,LDCMB
 SG_ HeadLghtLvlLeft_No_Rq : 7|12@0+ (1,0) [0|4095] "1/2 step"  LDCMC,LDCMA

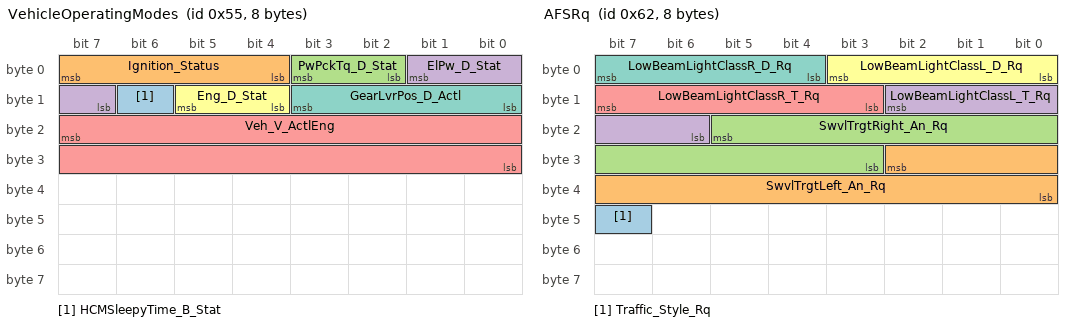
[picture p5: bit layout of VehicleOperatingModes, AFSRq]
BO_ 85 VehicleOperatingModes: 8 HCM
 SG_ HCMSleepyTime_B_Stat : 14|1@0+ (1,0) [0|1] ""  LDCMC,LDCMD,LDCMF,LDCME,LDCMB,LDCMA
 SG_ Ignition_Status : 7|4@0+ (1,0) [0|15] "SED"  LDCMC,LDCMD,LDCMF,LDCME,LDCMA,LDCMB
 SG_ PwPckTq_D_Stat : 3|2@0+ (1,0) [0|3] ""  LDCMC,LDCMD,LDCMF,LDCME,LDCMA,LDCMB
 SG_ ElPw_D_Stat : 1|3@0+ (1,0) [0|7] "SED"  LDCMC,LDCMD,LDCMF,LDCME,LDCMA,LDCMB
 SG_ Veh_V_ActlEng : 23|16@0+ (0.01,0) [0|655.35] "kph"  LDCME,LDCMF
 SG_ Eng_D_Stat : 13|2@0+ (1,0) [0|3] "SED"  LDCME,LDCMF
 SG_ GearLvrPos_D_Actl : 11|4@0+ (1,0) [0|15] "SED"  LDCME,LDCMF

BO_ 98 AFSRq: 8 HCM
 SG_ Traffic_Style_Rq : 47|1@0+ (1,0) [0|1] ""  LDCMC,LDCMD,LDCMA,LDCMB
 SG_ SwvlTrgtLeft_An_Rq : 26|11@0+ (0.04,-35) [-35|46.88] "Degrees"  LDCMC,LDCMD,LDCMA,LDCMB
 SG_ SwvlTrgtRight_An_Rq : 21|11@0+ (0.04,-35) [-35|46.88] "Degrees"  LDCMC,LDCMD,LDCMA,LDCMB
 SG_ LowBeamLightClassL_T_Rq : 10|5@0+ (200,0) [0|6200] "ms"  LDCMC,LDCMD,LDCMA,LDCMB
 SG_ LowBeamLightClassR_T_Rq : 15|5@0+ (200,0) [0|6200] "ms"  LDCMC,LDCMD,LDCMA,LDCMB
 SG_ LowBeamLightClassL_D_Rq : 3|4@0+ (1,0) [0|15] ""  LDCMC,LDCMD,LDCMA,LDCMB
 SG_ LowBeamLightClassR_D_Rq : 7|4@0+ (1,0) [0|15] ""  LDCMC,LDCMD,LDCMA,LDCMB

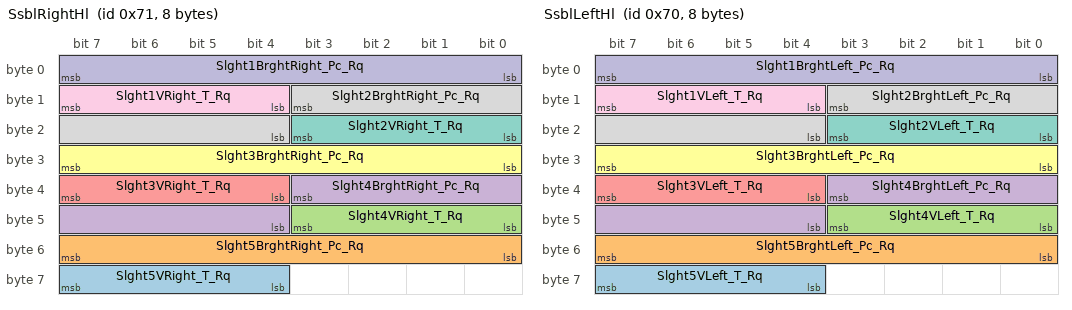
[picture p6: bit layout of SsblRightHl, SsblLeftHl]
BO_ 113 SsblRightHl: 8 HCM
 SG_ Slght5VRight_T_Rq : 63|4@0+ (500,0) [0|7500] "ms"  LDCMD,LDCMB
 SG_ Slght5BrghtRight_Pc_Rq : 55|8@0+ (0.5,0) [0|100] "%"  LDCMD,LDCMB
 SG_ Slght4VRight_T_Rq : 43|4@0+ (500,0) [0|7500] "ms"  LDCMD,LDCMB
 SG_ Slght4BrghtRight_Pc_Rq : 35|8@0+ (0.5,0) [0|100] "%"  LDCMD,LDCMB
 SG_ Slght3VRight_T_Rq : 39|4@0+ (500,0) [0|7500] "ms"  LDCMD,LDCMB
 SG_ Slght3BrghtRight_Pc_Rq : 31|8@0+ (0.5,0) [0|100] "%"  LDCMD,LDCMB
 SG_ Slght2VRight_T_Rq : 19|4@0+ (500,0) [0|7500] "ms"  LDCMD,LDCMB
 SG_ Slght2BrghtRight_Pc_Rq : 11|8@0+ (0.5,0) [0|100] "%"  LDCMD,LDCMB
 SG_ Slght1VRight_T_Rq : 15|4@0+ (500,0) [0|7500] "ms"  LDCMD,LDCMB
 SG_ Slght1BrghtRight_Pc_Rq : 7|8@0+ (0.5,0) [0|100] "%"  LDCMD,LDCMB

BO_ 112 SsblLeftHl: 8 HCM
 SG_ Slght5VLeft_T_Rq : 63|4@0+ (500,0) [0|7500] "ms"  LDCMC,LDCMA
 SG_ Slght5BrghtLeft_Pc_Rq : 55|8@0+ (0.5,0) [0|100] "%"  LDCMC,LDCMA
 SG_ Slght4VLeft_T_Rq : 43|4@0+ (500,0) [0|7500] "ms"  LDCMC,LDCMA
 SG_ Slght4BrghtLeft_Pc_Rq : 35|8@0+ (0.5,0) [0|100] "%"  LDCMC,LDCMA
 SG_ Slght3VLeft_T_Rq : 39|4@0+ (500,0) [0|7500] "ms"  LDCMC,LDCMA
 SG_ Slght3BrghtLeft_Pc_Rq : 31|8@0+ (0.5,0) [0|100] "%"  LDCMC,LDCMA
 SG_ Slght2VLeft_T_Rq : 19|4@0+ (500,0) [0|7500] "ms"  LDCMC,LDCMA
 SG_ Slght2BrghtLeft_Pc_Rq : 11|8@0+ (0.5,0) [0|100] "%"  LDCMC,LDCMA
 SG_ Slght1VLeft_T_Rq : 15|4@0+ (500,0) [0|7500] "ms"  LDCMC,LDCMA
 SG_ Slght1BrghtLeft_Pc_Rq : 7|8@0+ (0.5,0) [0|100] "%"  LDCMC,LDCMA

BO_ 2147484595 BodyInfo_3_HCM: 16 HCM
 SG_ DrStatRl_B_Actl : 48|1@0+ (1,0) [0|1] "SED"  LDCME,LDCMF
 SG_ DrStatRr_B_Actl : 49|1@0+ (1,0) [0|1] "SED"  LDCME,LDCMF
 SG_ DrStatInnrTgate_B_Actl : 58|1@0+ (1,0) [0|1] "SED"  LDCME,LDCMF
 SG_ DrStatPsngr_B_Actl : 60|1@0+ (1,0) [0|1] "SED"  LDCME,LDCMF
 SG_ DrStatDrv_B_Actl : 61|1@0+ (1,0) [0|1] "SED"  LDCME,LDCMF

BO_TX_BU_ 2015 : HCM,TSTR;
BO_TX_BU_ 1783 : HCM,TSTR;
BO_TX_BU_ 1782 : HCM,TSTR;

CM_ "HCM Private FD CAN Network";
CM_ BU_ LDCMC "Lighting Driver Control Module “A” - Left Side LDM";
CM_ BU_ LDCMD "Lighting Driver Control Module “B” - Right Side LDM";
CM_ BU_ LDCMF "Lighting Driver Control Module 'D' ";
CM_ BU_ LDCME "Lighting Driver Control Module 'C'";
CM_ BU_ CSDB "CAN Stepper Driver “B” - Right Side CAN-based Motor";
CM_ BU_ CSDA "CAN Stepper Driver “A” - Left Side CAN-based Motor";
CM_ BU_ HCM "Headlamp Control Module";
CM_ BU_ TSTR "Diagnostic Tester";
CM_ BU_ LDCMA "Lighting Driver Control Module “A” - Left Side LDM";
CM_ BU_ LDCMB "Lighting Driver Control Module “B” - Right Side LDM";
CM_ SG_ 785 CanMsg311_No_Crc "E2E Protection CRC";
CM_ SG_ 785 TurnLampFrOut_B_Stat2 "Provide TI unit status. Trigger TI feedback to BCM and TI general electircal failure DTC";
CM_ SG_ 769 CanMsg301_No_Crc "E2E Protection CRC";
CM_ SG_ 769 TurnLampFlOut_B_Stat2 "Provide TI unit status. Trigger TI feedback to BCM and TI general electircal failure DTC";
CM_ BO_ 125 "Message to transmit the status of the secondary front right headlamp in regards to leveling, LED outage, LDM status";
CM_ SG_ 125 LDM_HbFdbckRght_B_Stat2 "Feedback if lamp is actually executing a HB pending individual optical boundaries. (AHB Version after 3.0)";
CM_ SG_ 125 Hlr_Temp_Stat2 "Provide Headlamp Overtemperature Status.";
CM_ SG_ 125 Mdule2RightHl_side_Stat "Provide side detection status";
CM_ SG_ 125 Mdule2RightHl_Com_Stat "Provide physical CAN bus status. Trigger Physical CAN bus DTC";
CM_ SG_ 125 Mdule2Right_MPwr_B_Stat "Provide Main Power supply status. Triger Main Power Supply DTC.";
CM_ SG_ 125 Mdule2Right_LB_Pwr_B_Stat "Provide LB Power supply status.Triger LB Power Supply DTC";
CM_ SG_ 125 Hlr_SM_Stat2 "Provide SM unit status. Triger SM general electircal failure DTC";
CM_ SG_ 125 Hlr_SBL_Stat2 "Provide SBL unit status. Triger SBL general electircal failure DTC";
CM_ SG_ 125 Hlr_Pixel_Stat2 "Provide Pixel unit status. Triger Pixel general electircal failure DTC";
CM_ SG_ 125 Hlr_Fan_B_Stat2 "Provide fan status.Triger FAN DTC";
CM_ SG_ 125 Hlr_DRL_POS_Stat2 "Provide DRL_POS unit status. riger DRL general electircal failure DTC";
CM_ SG_ 125 Hlr_LvlMotor_Temp_Stat2 "Determing stepper temperature status";
CM_ SG_ 125 HeadLghtLvlRght_D_Stat2 "Command to start referencing run including leveling and beam shape changes. ";
CM_ SG_ 125 HeadLghtLvlRght_No_Stat2 "Command to move leveling. Given in half steps.";
CM_ SG_ 125 Mdule2RightFail_B_Stat "LDM Feedback of headlamp and LDM health status. This signal shall be used for DTC generation through HCM";
CM_ SG_ 125 Mdule2RightConfg_B_Stat "LDM Feedback of configuration state";
CM_ BO_ 124 "Message to transmit the status of the secondary front left headlamp in regards to leveling, LED outage, LDM status";
CM_ SG_ 124 LDM_HbFdbckLeft_B_Stat2 "Feedback if lamp is actually executing a HB pending individual optical boundaries. (AHB Version after 3.0)";
CM_ SG_ 124 HeadLghtLvlLeft_No_Stat2 "Command to move leveling. Given in half steps.";
CM_ SG_ 124 Hll_Temp_Stat2 "Provide Headlamp Overtemperature Status.";
CM_ SG_ 124 Mdule2LeftHl_side_Stat "Provide side detection status";
CM_ SG_ 124 Mdule2LeftHl_Com_Stat "Provide physical CAN bus status. Trigger Physical CAN bus DTC";
CM_ SG_ 124 Mdule2Left_MPwr_B_Stat "Provide Main Power supply status. Triger Main Power Supply DTC.";
CM_ SG_ 124 Mdule2Left_LB_Pwr_B_Stat "Provide LB Power supply status.Triger LB Power Supply DTC";
CM_ SG_ 124 Hll_SM_Stat2 "Provide SM unit status. Triger SM general electircal failure DTC";
CM_ SG_ 124 Hll_SBL_Stat2 "Provide SBL unit status. Triger SBL general electircal failure DTC";
CM_ SG_ 124 Hll_Pixel_Stat2 "Provide Pixel unit status. Triger Pixel general electircal failure DTC";
CM_ SG_ 124 Hll_Fan_B_Stat2 "Provide fan status.Triger FAN DTC";
CM_ SG_ 124 Hll_DRL_POS_Stat2 "Provide DRL_POS unit status. riger DRL general electircal failure DTC";
CM_ SG_ 124 Hll_LvlMotor_Temp_Stat2 "Determing stepper motor temperature status";
CM_ SG_ 124 HeadLghtLvlLeft_D_Stat2 "Command to start referencing run including leveling and beam shape changes. ";
CM_ SG_ 124 Mdule2LeftFail_B_Stat "LDM Feedback of headlamp and LDM health status. This signal shall be used for DTC generation through HCM";
CM_ SG_ 124 Mdule2LeftConfg_B_Stat "LDM Feedback of configuration state";
CM_ BO_ 123 "Message to transmit the status of the front right headlamp in regards to leveling, LED outage, LDM status";
CM_ BO_ 122 "Message to transmit the status of the front left headlamp in regards to leveling, LED outage, LDM status";
CM_ SG_ 102 Hbm6TrnstnRight_An_Rq "Spot transition zone right (border sharpness and spot forerun)";
CM_ SG_ 102 Hbm6TrnstnLeft_An_Rq "Spot transition zone left (border sharpness and spot forerun)";
CM_ SG_ 102 Hbm6RightLghtRigh_An_Rq "Target angle of the spot given an imaginary rectangle from the current vehicle H-H line (horizon). in driving direction, + to the left side, - to the right side";
CM_ SG_ 102 Hbm6RightLghtLeft_An_Rq "Target angle of the spot given an imaginary rectangle from the current vehicle H-H line (horizon). in driving direction, + to the left side, - to the right side";
CM_ SG_ 102 Hbm6Ramping_T_Rq "Theatre fading speed command to HighBeam. Time is defining [s/100% activation of requested brightness]";
CM_ SG_ 102 Hbm6LeftLghtRight_An_Rq "Target angle of the spot given an imaginary rectangle from the current vehicle H-H line (horizon). in driving direction, + to the left side, - to the right side";
CM_ SG_ 102 Hbm6LeftLghtLeft_An_Rq "Target angle of the spot given an imaginary rectangle from the current vehicle H-H line (horizon). in driving direction, + to the left side, - to the right side";
CM_ SG_ 102 Hbm6BrdrTop_An_Rq "Target angle of the spot given an imaginary rectangle from the current vehicle H-H line (horizon). + to the bottom, - to the top";
CM_ SG_ 102 Hbm6BrdrBottom_An_Rq "Target angle of the spot given an imaginary rectangle from the current vehicle H-H line (horizon). + to the bottom, - to the top";
CM_ SG_ 102 Hbm5TrnstnRight_An_Rq "Spot transition zone right (border sharpness and spot forerun)";
CM_ SG_ 102 Hbm5TrnstnLeft_An_Rq "Spot transition zone left (border sharpness and spot forerun)";
CM_ SG_ 102 Hbm5RightLghtRigh_An_Rq "Target angle of the spot given an imaginary rectangle from the current vehicle H-H line (horizon). in driving direction, + to the left side, - to the right side";
CM_ SG_ 102 Hbm5RightLghtLeft_An_Rq "Target angle of the spot given an imaginary rectangle from the current vehicle H-H line (horizon). in driving direction, + to the left side, - to the right side";
CM_ SG_ 102 Hbm5Ramping_T_Rq "Theatre fading speed command to HighBeam. Time is defining [s/100% activation of requested brightness]";
CM_ SG_ 102 Hbm5LeftLghtRight_An_Rq "Target angle of the spot given an imaginary rectangle from the current vehicle H-H line (horizon). in driving direction, + to the left side, - to the right side";
CM_ SG_ 102 Hbm5LeftLghtLeft_An_Rq "Target angle of the spot given an imaginary rectangle from the current vehicle H-H line (horizon). in driving direction, + to the left side, - to the right side";
CM_ SG_ 102 Hbm5BrdrTop_An_Rq "Target angle of the spot given an imaginary rectangle from the current vehicle H-H line (horizon). + to the bottom, - to the top";
CM_ SG_ 102 Hbm5BrdrBottom_An_Rq "Target angle of the spot given an imaginary rectangle from the current vehicle H-H line (horizon). + to the bottom, - to the top";
CM_ SG_ 102 Hbm4TrnstnRight_An_Rq "Spot transition zone right (border sharpness and spot forerun)";
CM_ SG_ 102 Hbm4TrnstnLeft_An_Rq "Spot transition zone left (border sharpness and spot forerun)";
CM_ SG_ 102 Hbm4RightLghtRigh_An_Rq "Target angle of the spot given an imaginary rectangle from the current vehicle H-H line (horizon). in driving direction, + to the left side, - to the right side";
CM_ SG_ 102 Hbm4RightLghtLeft_An_Rq "Target angle of the spot given an imaginary rectangle from the current vehicle H-H line (horizon). in driving direction, + to the left side, - to the right side";
CM_ SG_ 102 Hbm4Ramping_T_Rq "Theatre fading speed command to HighBeam. Time is defining [s/100% activation of requested brightness]";
CM_ SG_ 102 Hbm4LeftLghtRight_An_Rq "Target angle of the spot given an imaginary rectangle from the current vehicle H-H line (horizon). in driving direction, + to the left side, - to the right side";
CM_ SG_ 102 Hbm4LeftLghtLeft_An_Rq "Target angle of the spot given an imaginary rectangle from the current vehicle H-H line (horizon). in driving direction, + to the left side, - to the right side";
CM_ SG_ 102 Hbm4BrdrTop_An_Rq "Target angle of the spot given an imaginary rectangle from the current vehicle H-H line (horizon). + to the bottom, - to the top";
CM_ SG_ 102 Hbm4BrdrBottom_An_Rq "Target angle of the spot given an imaginary rectangle from the current vehicle H-H line (horizon). + to the bottom, - to the top";
CM_ SG_ 102 Hbm3TrnstnRight_An_Rq "Spot transition zone right (border sharpness and spot forerun)";
CM_ SG_ 102 Hbm3TrnstnLeft_An_Rq "Spot transition zone left (border sharpness and spot forerun)";
CM_ SG_ 102 Hbm3RightLghtRigh_An_Rq "Target angle of the spot given an imaginary rectangle from the current vehicle H-H line (horizon). in driving direction, + to the left side, - to the right side";
CM_ SG_ 102 Hbm3RightLghtLeft_An_Rq "Target angle of the spot given an imaginary rectangle from the current vehicle H-H line (horizon). in driving direction, + to the left side, - to the right side";
CM_ SG_ 102 Hbm3Ramping_T_Rq "Theatre fading speed command to HighBeam. Time is defining [s/100% activation of requested brightness]";
CM_ SG_ 102 Hbm3LeftLghtRight_An_Rq "Target angle of the spot given an imaginary rectangle from the current vehicle H-H line (horizon). in driving direction, + to the left side, - to the right side";
CM_ SG_ 102 Hbm3BrdrTop_An_Rq "Target angle of the spot given an imaginary rectangle from the current vehicle H-H line (horizon). + to the bottom, - to the top";
CM_ SG_ 102 Hbm3BrdrBottom_An_Rq "Target angle of the spot given an imaginary rectangle from the current vehicle H-H line (horizon). + to the bottom, - to the top";
CM_ SG_ 102 Hbm2BrdrBottom_An_Rq "Target angle of the spot given an imaginary rectangle from the current vehicle H-H line (horizon). + to the bottom, - to the top";
CM_ SG_ 102 Hbm1BrdrBottom_An_Rq "Target angle of the spot given an imaginary rectangle from the current vehicle H-H line (horizon). + to the bottom, - to the top";
CM_ SG_ 102 Hbm2BrdrTop_An_Rq "Target angle of the spot given an imaginary rectangle from the current vehicle H-H line (horizon). + to the bottom, - to the top";
CM_ SG_ 102 Hbm1BrdrTop_An_Rq "Target angle of the spot given an imaginary rectangle from the current vehicle H-H line (horizon). + to the bottom, - to the top";
CM_ SG_ 102 Hbm2TrnstnRight_An_Rq "Spot tranisition zone right (border sharpness and spot forerun)";
CM_ SG_ 102 Hbm1TrnstnRight_An_Rq "Spot transition zone right (border sharpness and spot forerun)";
CM_ SG_ 102 Hbm2RightLghtRigh_An_Rq "Target angle of the spot given an imaginary rectangle from the current vehicle H-H line (horizon). in driving direction, + to the left side, - to the right side";
CM_ SG_ 102 Hbm1RightLghtRigh_An_Rq "Target angle of the spot given an imaginary rectangle from the current vehicle H-H line (horizon). in driving direction, + to the left side, - to the right side";
CM_ SG_ 102 Hbm2LeftLghtRight_An_Rq "Target angle of the spot given an imaginary rectangle from the current vehicle H-H line (horizon). in driving direction, + to the left side, - to the right side";
CM_ SG_ 102 Hbm1LeftLghtRight_An_Rq "Target angle of the spot given an imaginary rectangle from the current vehicle H-H line (horizon). in driving direction, + to the left side, - to the right side";
CM_ SG_ 102 Hbm2TrnstnLeft_An_Rq "Spot transition zone left (border sharpness and spot forerun)";
CM_ SG_ 102 Hbm1TrnstnLeft_An_Rq "Spot transition zone left (border sharpness and spot forerun)";
CM_ SG_ 102 Hbm2RightLghtLeft_An_Rq "Target angle of the spot given an imaginary rectangle from the current vehicle H-H line (horizon). in driving direction, + to the left side, - to the right side";
CM_ SG_ 102 Hbm1RightLghtLeft_An_Rq "Target angle of the spot given an imaginary rectangle from the current vehicle H-H line (horizon). in driving direction, + to the left side, - to the right side";
CM_ SG_ 102 Hbm3LeftLghtLeft_An_Rq "Target angle of the spot given an imaginary rectangle from the current vehicle H-H line (horizon). in driving direction, + to the left side, - to the right side";
CM_ SG_ 102 Hbm2LeftLghtLeft_An_Rq "Target angle of the spot given an imaginary rectangle from the current vehicle H-H line (horizon). in driving direction, + to the left side, - to the right side";
CM_ SG_ 102 Hbm1LeftLghtLeft_An_Rq "Target angle of the spot given an imaginary rectangle from the current vehicle H-H line (horizon). in driving direction, + to the left side, - to the right side";
CM_ SG_ 102 Hbm2Ramping_T_Rq "Theatre fading speed command to HighBeam. Time is defining [s/100% activation of requested brightness]";
CM_ SG_ 102 Hbm1Ramping_T_Rq "Theatre fading speed command to HighBeam. Time is defining [s/100% activation of requested brightness]";
CM_ SG_ 102 Hbm6Mde_D_Rq "High Beam Spot Mode";
CM_ SG_ 102 Hbm5Mde_D_Rq "High Beam Spot Mode";
CM_ SG_ 102 Hbm4Mde_D_Rq "High Beam Spot Mode";
CM_ SG_ 102 Hbm3Mde_D_Rq "High Beam Spot Mode";
CM_ SG_ 102 Hbm2Mde_D_Rq "High Beam Spot Mode";
CM_ SG_ 102 Hbm1Mde_D_Rq "High Beam Spot Mode";
CM_ SG_ 102 HeadLghtHi_T_Rq "Theatre fading speed command to HighBeam. Time is defining [s/100% activation of requested brightness]";
CM_ SG_ 102 HeadLghtHi_D_Rq "High Beam On/Off Request";
CM_ SG_ 784 TurnLampFrOut_B_Stat "Provide TI unit status. Trigger TI feedback to BCM and TI general electircal failure DTC";
CM_ SG_ 784 CanMsg310_No_Crc "E2E Protection CRC";
CM_ SG_ 768 TurnLampFlOut_B_Stat "Provide TI unit status. Trigger TI feedback to BCM and TI general electircal failure DTC";
CM_ SG_ 768 CanMsg300_No_Crc "E2E Protection CRC";
CM_ BO_ 800 "HS2/FD1 origin LB command ";
CM_ SG_ 800 CanMsg320_No_Crc "E2E Protection CRC";
CM_ SG_ 800 TurnLghtRight_D_Rq "Turn Request Command for Right Turn Indicator";
CM_ SG_ 800 TurnLghtLeft_D_Rq "Turn Request Command for Left Turn Indicator";
CM_ BO_ 121 "Message to transmit the status of the front right headlamp in regards to leveling, LED outage, LDM status";
CM_ SG_ 121 Hlr_DblMotor_Volt_D_Stat "Determing stepper motor voltage status";
CM_ SG_ 121 DblMtrRight_Motion_B_Stat "Feedback to indicate actual moving status of DBL motor";
CM_ SG_ 121 SwvlTrgtRight_An_D_Stat "Dynamic bending light target angle command right headlamp";
CM_ SG_ 121 Hlr_DblMotor_Temp_Stat "Determing stepper motor temperature status";
CM_ SG_ 121 HeadLghtDblRght_D_Stat "Command to start referencing run including leveling and beam shape changes. ";
CM_ BO_ 120 "Message to transmit the status of the front left headlamp in regards to leveling, LED outage, LDM status";
CM_ SG_ 120 Hll_DblMotor_Volt_D_Stat "Determing stepper motor voltage status";
CM_ SG_ 120 DblMtrLeft_Motion_B_Stat "Feedback to indicate actual moving status of DBL motor";
CM_ SG_ 120 SwvlTrgtLeft_An_D_Stat "Dynamic bending light target angle command left headlamp";
CM_ SG_ 120 Hll_DblMotor_Temp_Stat "Determing stepper motor temperature status";
CM_ SG_ 120 HeadLghtDbllLeft_D_Stat "Command to start referencing run including leveling and beam shape changes. ";
CM_ BO_ 119 "Message for headlamp leveling target data and headlamp reference run for leveling, swiveling and light modes";
CM_ SG_ 119 HeadLghtDblRghtRef_D_Rq "Command to start referencing run including leveling and beam shape changes. ";
CM_ SG_ 119 HeadLghtDblLeftRef_D_Rq "Command to start referencing run including leveling and beam shape changes. ";
CM_ SG_ 119 MtrSwvlTrgtRight_An_Rq "Dynamic bending light target angle command right headlamp. In a default configuration, a positive angle command denotes a movement to the left from the driver's point of view.";
CM_ SG_ 119 MtrSwvlTrgtLeft_An_Rq "Dynamic bending light target angle command left headlamp. In a default configuration, a positive angle command denotes a movement to the left from the driver's point of view.";
CM_ BO_ 80 "Base Lighting Feature Control";
CM_ SG_ 80 ExtLghtAnmtn_D_Rq "Required determining the powertrain start/ stop status preparing for battery low voltage state";
CM_ SG_ 80 DrlPos4_Actv_Rf_Rq "Right DRL and POS activation control of second part of the string";
CM_ SG_ 80 DrlPos4_Actv_Lf_Rq "Left DRL and POS activation control of second part of the string";
CM_ SG_ 80 DrlPos3_Actv_Rf_Rq "Right DRL and POS activation control of first part of the string";
CM_ SG_ 80 ExtLghtFront_D_RqBody "Tourist mode. 
0x01 changes the vehicle default beam shape to the opposite. 
Default beam shape is dependant on the traffic side the vehicle has been licensed to";
CM_ SG_ 80 Front_Fog_Actv_Rq "Front Fog activation request.";
CM_ SG_ 80 WfSubstate_D_Stat "Welcome Farewell Substate";
CM_ SG_ 80 WfSuperstate_D_Stat "Welcome Farewell Superstate";
CM_ SG_ 80 Drl_Pos_Actv_Fade_Rf_Rq "DRL and POS activation fading time in ms/100% for right headlamp";
CM_ SG_ 80 SideMarker_Actv_Rq "Status of LB function. Information/Status only.";
CM_ SG_ 80 Drl_Pos_Actv_Fade_Lf_Rq "DRL and POS activation fading time in ms/100% for left headlamp";
CM_ SG_ 80 DrlPos2_Actv_Rf_Rq "Right DRL and POS activation control of second part of the string";
CM_ SG_ 80 DrlPos1_Actv_Rf_Rq "Right DRL and POS activation control of first part of the string";
CM_ SG_ 80 DrlPos2_Actv_Lf_Rq "Left DRL and POS activation control of second part of the string";
CM_ SG_ 80 DrlPos1_Actv_Lf_Rq "Left DRL and POS activation control of first part of the string";
CM_ BO_ 117 "Message to transmit the status of the front right headlamp in regards to leveling, LED outage, LDM status";
CM_ SG_ 117 LDM_HbFdbckRght_B_Stat "Feedback if lamp is actually executing a HB pending individual optical boundaries. (AHB Version after 3.0)";
CM_ SG_ 117 Hlr_Temp_Stat "Provide Headlamp Overtemperature Status.";
CM_ SG_ 117 Mdule1RightHl_side_Stat "Provide side detection status";
CM_ SG_ 117 Mdule1RightHl_Com_Stat "Provide physical CAN bus status. Trigger Physical CAN bus DTC";
CM_ SG_ 117 Mdule1Right_MPwr_B_Stat "Provide Main Power supply status. Triger Main Power Supply DTC.";
CM_ SG_ 117 Mdule1Right_LB_Pwr_B_Stat "Provide LB Power supply status.Triger LB Power Supply DTC";
CM_ SG_ 117 Hlr_SM_Stat "Provide SM unit status. Triger SM general electircal failure DTC";
CM_ SG_ 117 Hlr_SBL_Stat "Provide SBL unit status. Triger SBL general electircal failure DTC";
CM_ SG_ 117 Hlr_Pixel_Stat "Provide Pixel unit status. Triger Pixel general electircal failure DTC";
CM_ SG_ 117 Hlr_Fan_B_Stat "Provide fan status.Triger FAN DTC";
CM_ SG_ 117 Hlr_DRL_POS_Stat "Provide DRL_POS unit status. riger DRL general electircal failure DTC";
CM_ SG_ 117 Hlr_LvlMotor_Temp_Stat "Determing stepper temperature status";
CM_ SG_ 117 HeadLghtLvlRght_D_Stat "Command to start referencing run including leveling and beam shape changes. ";
CM_ SG_ 117 HeadLghtLvlRght_No_Stat "Command to move leveling. Given in half steps.";
CM_ SG_ 117 Mdule1RightFail_B_Stat "LDM Feedback of headlamp and LDM health status. This signal shall be used for DTC generation through HCM";
CM_ SG_ 117 Mdule1RightConfg_B_Stat "LDM Feedback of configuration state";
CM_ BO_ 116 "Message to transmit the status of the front left headlamp in regards to leveling, LED outage, LDM status";
CM_ SG_ 116 LDM_HbFdbckLeft_B_Stat "Feedback if lamp is actually executing a HB pending individual optical boundaries. (AHB Version after 3.0)";
CM_ SG_ 116 HeadLghtLvlLeft_No_Stat "Command to move leveling. Given in half steps.";
CM_ SG_ 116 Hll_Temp_Stat "Provide Headlamp Overtemperature Status.";
CM_ SG_ 116 Mdule1LeftHl_side_Stat "Provide side detection status";
CM_ SG_ 116 Mdule1LeftHl_Com_Stat "Provide physical CAN bus status. Trigger Physical CAN bus DTC";
CM_ SG_ 116 Mdule1Left_MPwr_B_Stat "Provide Main Power supply status. Triger Main Power Supply DTC.";
CM_ SG_ 116 Mdule1Left_LB_Pwr_B_Stat "Provide LB Power supply status.Triger LB Power Supply DTC";
CM_ SG_ 116 Hll_SM_Stat "Provide SM unit status. Triger SM general electircal failure DTC";
CM_ SG_ 116 Hll_SBL_Stat "Provide SBL unit status. Triger SBL general electircal failure DTC";
CM_ SG_ 116 Hll_Pixel_Stat "Provide Pixel unit status. Triger Pixel general electircal failure DTC";
CM_ SG_ 116 Hll_Fan_B_Stat "Provide fan status.Triger FAN DTC";
CM_ SG_ 116 Hll_DRL_POS_Stat "Provide DRL_POS unit status. riger DRL general electircal failure DTC";
CM_ SG_ 116 Hll_LvlMotor_Temp_Stat "Determing stepper motor temperature status";
CM_ SG_ 116 HeadLghtLvlLeft_D_Stat "Command to start referencing run including leveling and beam shape changes. ";
CM_ SG_ 116 Mdule1LeftFail_B_Stat "LDM Feedback of headlamp and LDM health status. This signal shall be used for DTC generation through HCM";
CM_ SG_ 116 Mdule1LeftConfg_B_Stat "LDM Feedback of configuration state";
CM_ BO_ 118 "Message for headlamp leveling target data and headlamp reference run for leveling, swiveling and light modes";
CM_ SG_ 118 HeadLghtLvlRghtRef_D_Rq "Command to start referencing run including leveling and beam shape changes. ";
CM_ SG_ 118 HeadLghtLvlLeftRef_D_Rq "Command to start referencing run including leveling and beam shape changes. ";
CM_ SG_ 118 HeadLghtLvlRight_No_Rq "Command to move leveling. Given in half  steps.";
CM_ SG_ 118 HeadLghtLvlLeft_No_Rq "Command to move leveling. Given in half steps.";
CM_ BO_ 85 "Vehicle operation modes for Microhybrid / StartStop low voltage behavior";
CM_ SG_ 85 Ignition_Status "Ignition status";
CM_ SG_ 85 PwPckTq_D_Stat "Required determining the powertrain start/ stop status preparing for battery low voltage state";
CM_ SG_ 85 ElPw_D_Stat "Required determining the powertrain start/ stop status preparing for battery low voltage state";
CM_ BO_ 98 "Low Beam Shape definition, Swiveling Target Angle and Tourist Mode request (Traffic Style)";
CM_ SG_ 98 Traffic_Style_Rq "Tourist mode. 
0x01 changes the vehicle default beam shape to the opposite. 
Default beam shape is dependant on the traffic side the vehicle has been licensed to";
CM_ SG_ 98 SwvlTrgtLeft_An_Rq "Dynamic bending light target angle command left headlamp";
CM_ SG_ 98 SwvlTrgtRight_An_Rq "Dynamic bending light target angle command right headlamp";
CM_ SG_ 98 LowBeamLightClassL_T_Rq "Command to transition speed of one Speed dependend light mode state to another . Does not change the SBL/ SSBL light sources.";
CM_ SG_ 98 LowBeamLightClassR_T_Rq "Command to transition speed of one Speed dependend light mode state to another . Does not change the SBL/ SSBL light sources.";
CM_ SG_ 98 LowBeamLightClassL_D_Rq "Command to change the Speed dependend light mode state. Does not change the SBL/ SSBL light sources.";
CM_ SG_ 98 LowBeamLightClassR_D_Rq "Command to change the Speed dependend light mode state. Does not change the SBL/ SSBL light sources.";
CM_ BO_ 113 "Message to control the SBL and SSBL on right headlamp";
CM_ SG_ 113 Slght5VRight_T_Rq "Supplementary light source (SSBL) rate of change of activation [ms to 100%]";
CM_ SG_ 113 Slght5BrghtRight_Pc_Rq "Supplementary light source (SSBL) rate of activation";
CM_ SG_ 113 Slght4VRight_T_Rq "Supplementary light source (SSBL) rate of change of activation [ms to 100%]";
CM_ SG_ 113 Slght4BrghtRight_Pc_Rq "Supplementary light source (SSBL) rate of activation";
CM_ SG_ 113 Slght3VRight_T_Rq "Supplementary light source (SSBL) rate of change of activation [ms to 100%]";
CM_ SG_ 113 Slght3BrghtRight_Pc_Rq "Supplementary light source (SSBL) rate of activation";
CM_ SG_ 113 Slght2VRight_T_Rq "Supplementary light source (SSBL) rate of change of activation [ms to 100%]";
CM_ SG_ 113 Slght2BrghtRight_Pc_Rq "Supplementary light source (SSBL) rate of activation";
CM_ SG_ 113 Slght1VRight_T_Rq "Supplementary light source (SSBL) rate of change of activation [ms to 100%]";
CM_ SG_ 113 Slght1BrghtRight_Pc_Rq "Supplementary light source (SSBL or SBL) rate of activation";
CM_ BO_ 112 "Message to control the SBL and SSBL on left headlamp";
CM_ SG_ 112 Slght5VLeft_T_Rq "Supplementary light source (SSBL) rate of change of activation [ms to 100%]";
CM_ SG_ 112 Slght5BrghtLeft_Pc_Rq "Supplementary light source (SSBL) rate of activation";
CM_ SG_ 112 Slght4VLeft_T_Rq "Supplementary light source (SSBL) rate of change of activation [ms to 100%]";
CM_ SG_ 112 Slght4BrghtLeft_Pc_Rq "Supplementary light source (SSBL) rate of activation";
CM_ SG_ 112 Slght3VLeft_T_Rq "Supplementary light source (SSBL) rate of change of activation [ms to 100%]";
CM_ SG_ 112 Slght3BrghtLeft_Pc_Rq "Supplementary light source (SSBL) rate of activation";
CM_ SG_ 112 Slght2VLeft_T_Rq "Supplementary light source (SSBL) rate of change of activation [ms to 100%]";
CM_ SG_ 112 Slght2BrghtLeft_Pc_Rq "Supplementary light source (SSBL) rate of activation";
CM_ SG_ 112 Slght1VLeft_T_Rq "Supplementary light source (SSBL) rate of change of activation [ms to 100%]";
CM_ SG_ 112 Slght1BrghtLeft_Pc_Rq "Supplementary light source (SSBL or SBL) rate of activation";
BA_DEF_ BO_  "FrameRouting" STRING ;
BA_DEF_ BO_  "VFrameFormat" ENUM  "StandardCAN","ExtendedCAN","reserved","reserved","reserved","reserved","reserved","reserved","reserved","reserved","reserved","reserved","reserved","reserved","StandardCAN_FD","ExtendedCAN_FD";
BA_DEF_  "BusType" STRING ;
BA_DEF_ SG_  "GenSigSendType" ENUM  "Cyclic","OnWrite","vector_leerstring","OnChange","vector_leerstring","IfActive","vector_leerstring","NoSigSendType";
BA_DEF_ SG_  "GenSigInactiveValue" INT 0 100000;
BA_DEF_ SG_  "WakeupSignal" ENUM  "No","Yes";
BA_DEF_ SG_  "UsedOnPgmDBC" ENUM  "No","Yes";
BA_DEF_ SG_  "GenSigStartValue" INT 0 1000000000;
BA_DEF_ SG_  "ContentDependant" ENUM  "No","Yes";
BA_DEF_ SG_  "MetaData" ENUM  "No","Yes";
BA_DEF_ SG_  "U_U554_MCA_MY22_Rx" ENUM  "No","Yes";
BA_DEF_ SG_  "U_C519_MCA_MY22_Rx" ENUM  "No","Yes";
BA_DEF_ SG_  "U_U554_MCA_MY22_Tx" ENUM  "No","Yes";
BA_DEF_ SG_  "U_C519_MCA_MY22_Tx" ENUM  "No","Yes";
BA_DEF_ SG_  "U_U611_U625_MY20_Phev_Tx" ENUM  "No","Yes";
BA_DEF_ SG_  "GenSigTimeoutTime_HCM_SUBNET" INT 0 100000;
BA_DEF_ SG_  "GenSigTimeoutTime_X_LDMFR1" INT 0 100000;
BA_DEF_ SG_  "GenSigTimeoutTime_X_LDMFL1" INT 0 100000;
BA_DEF_ BO_  "GenMsgILSupport" ENUM  "No","Yes";
BA_DEF_ BO_  "DiagResponse" ENUM  "No","Yes";
BA_DEF_ BO_  "DiagRequest" ENUM  "No","Yes";
BA_DEF_ BO_  "TpTxIndex" INT 0 536870911;
BA_DEF_ BO_  "DiagState" ENUM  "No","Yes";
BA_DEF_ BO_  "GenMsgSendType" ENUM  "FixedPeriodic","Event","EnabledPeriodic","NotUsed","NotUsed","EventPeriodic","NotUsed","NotUsed","NoMsgSendType";
BA_DEF_ BO_  "GenMsgCycleTime" INT 0 100000;
BA_DEF_ BO_  "GenMsgDelayTime" INT 0 1000;
BA_DEF_ BO_  "GenMsgNrOfRepetition" INT 0 100;
BA_DEF_ BO_  "EventRateOfChange" INT 10 10000;
BA_DEF_ BO_  "NetworkInitialization" ENUM  "No","Yes";
BA_DEF_ BO_  "OvtpPushApplication" ENUM  "FALSE","TRUE";
BA_DEF_ BU_  "PackageID" STRING ;
BA_DEF_ BU_  "NosPackage" ENUM  "None","I3_1","I3_2","1.0.1","RP","EuCD","Volcano","I3_3","FNOS_Autosar";
BA_DEF_ BU_  "ILUsed" ENUM  "No","Yes";
BA_DEF_ BU_  "NmStationAddress" INT 0 255;
BA_DEF_ BU_  "EOL_SB_Flash" ENUM  "GGDS","GDS","NONE","vector_leerstring";
BA_DEF_ BU_  "DiagNode" ENUM  "GGDS","GDS","NONE";
BA_DEF_ BU_  "PowerType" ENUM  "Switched","Latched","Sleep","vector_leerstring","vector_leerstring";
BA_DEF_ BU_  "NmAsrNodeIdentifier" HEX 128 255;
BA_DEF_ BU_  "NodeStartUpTime" INT 0 10000;
BA_DEF_ BU_  "NodeWakeUpTime" INT 0 10000;
BA_DEF_ BU_  "Terminator" ENUM  "No","Yes";
BA_DEF_ BU_  "OvtpEcuAddress" INT 0 1022;
BA_DEF_ BU_  "OvtpOperationMode" ENUM  "SERVER","CLIENT";
BA_DEF_  "NmMessageCount" INT 0 128;
BA_DEF_  "NmBaseAddress" HEX 1280 1280;
BA_DEF_  "VersionYear" INT 2000 3000;
BA_DEF_  "VersionMonth" INT 1 12;
BA_DEF_  "Manufacturer" STRING ;
BA_DEF_  "VersionDay" INT 1 31;
BA_DEF_  "DBName" STRING ;
BA_DEF_  "NmAsrBaseAddress" HEX 1408 1408;
BA_DEF_  "NmAsrMessageCount" INT 128 128;
BA_DEF_  "NetworkSpeed" ENUM  "500kBits/s","125kBit/s";
BA_DEF_  "NmType" STRING ;
BA_DEF_  "CMDB_Version" STRING ;
BA_DEF_  "StarNetworkGwType" ENUM  "0=NotDefined","1=HS1","2=HS2","3=HS3","4=HS4","5=HS5","6=MS1","7=HS6","8=HS7","9=MS2";
BA_DEF_  "VersionNumber" INT 0 10000;
BA_DEF_DEF_  "FrameRouting" "";
BA_DEF_DEF_  "VFrameFormat" "ExtendedCAN_FD";
BA_DEF_DEF_  "BusType" "";
BA_DEF_DEF_  "GenSigSendType" "NoSigSendType";
BA_DEF_DEF_  "GenSigInactiveValue" 0;
BA_DEF_DEF_  "WakeupSignal" "No";
BA_DEF_DEF_  "UsedOnPgmDBC" "Yes";
BA_DEF_DEF_  "GenSigStartValue" 0;
BA_DEF_DEF_  "ContentDependant" "No";
BA_DEF_DEF_  "MetaData" "No";
BA_DEF_DEF_  "U_U554_MCA_MY22_Rx" "No";
BA_DEF_DEF_  "U_C519_MCA_MY22_Rx" "No";
BA_DEF_DEF_  "U_U554_MCA_MY22_Tx" "No";
BA_DEF_DEF_  "U_C519_MCA_MY22_Tx" "No";
BA_DEF_DEF_  "U_U611_U625_MY20_Phev_Tx" "No";
BA_DEF_DEF_  "GenSigTimeoutTime_HCM_SUBNET" 5000;
BA_DEF_DEF_  "GenSigTimeoutTime_X_LDMFR1" 5000;
BA_DEF_DEF_  "GenSigTimeoutTime_X_LDMFL1" 5000;
BA_DEF_DEF_  "GenMsgILSupport" "Yes";
BA_DEF_DEF_  "DiagResponse" "No";
BA_DEF_DEF_  "DiagRequest" "No";
BA_DEF_DEF_  "TpTxIndex" 0;
BA_DEF_DEF_  "DiagState" "No";
BA_DEF_DEF_  "GenMsgSendType" "NoMsgSendType";
BA_DEF_DEF_  "GenMsgCycleTime" 0;
BA_DEF_DEF_  "GenMsgDelayTime" 20;
BA_DEF_DEF_  "GenMsgNrOfRepetition" 1;
BA_DEF_DEF_  "EventRateOfChange" 10000;
BA_DEF_DEF_  "NetworkInitialization" "Yes";
BA_DEF_DEF_  "OvtpPushApplication" "FALSE";
BA_DEF_DEF_  "PackageID" "08.05.00.00.71.xx.xx.rr.00.00";
BA_DEF_DEF_  "NosPackage" "I3_3";
BA_DEF_DEF_  "ILUsed" "Yes";
BA_DEF_DEF_  "NmStationAddress" 0;
BA_DEF_DEF_  "EOL_SB_Flash" "GGDS";
BA_DEF_DEF_  "DiagNode" "GGDS";
BA_DEF_DEF_  "PowerType" "Switched";
BA_DEF_DEF_  "NmAsrNodeIdentifier" 128;
BA_DEF_DEF_  "NodeStartUpTime" 250;
BA_DEF_DEF_  "NodeWakeUpTime" 10;
BA_DEF_DEF_  "Terminator" "No";
BA_DEF_DEF_  "OvtpEcuAddress" 0;
BA_DEF_DEF_  "OvtpOperationMode" "SERVER";
BA_DEF_DEF_  "NmMessageCount" 128;
BA_DEF_DEF_  "NmBaseAddress" 1280;
BA_DEF_DEF_  "VersionYear" 2011;
BA_DEF_DEF_  "VersionMonth" 1;
BA_DEF_DEF_  "Manufacturer" "Ford";
BA_DEF_DEF_  "VersionDay" 1;
BA_DEF_DEF_  "DBName" "";
BA_DEF_DEF_  "NmAsrBaseAddress" 1408;
BA_DEF_DEF_  "NmAsrMessageCount" 128;
BA_DEF_DEF_  "NetworkSpeed" "500kBits/s";
BA_DEF_DEF_  "NmType" "Ford-OSEK";
BA_DEF_DEF_  "CMDB_Version" "v11.01";
BA_DEF_DEF_  "StarNetworkGwType" "0=NotDefined";
BA_DEF_DEF_  "VersionNumber" 1;
BA_ "BusType" "CAN FD";
BA_ "VersionNumber" 10;
BA_ "CMDB_Version" "FNV3_v22.10";
BA_ "VersionDay" 14;
BA_ "VersionMonth" 11;
BA_ "VersionYear" 2022;
BA_ "DBName" "FDCAN_LightingBus";
BA_ "OvtpEcuAddress" BU_ LDCMC 79;
BA_ "Terminator" BU_ LDCMC 1;
BA_ "NodeStartUpTime" BU_ LDCMC 200;
BA_ "NmStationAddress" BU_ LDCMC 125;
BA_ "OvtpEcuAddress" BU_ LDCMD 78;
BA_ "Terminator" BU_ LDCMD 1;
BA_ "NodeStartUpTime" BU_ LDCMD 200;
BA_ "NmStationAddress" BU_ LDCMD 122;
BA_ "NmStationAddress" BU_ LDCMF 77;
BA_ "NmStationAddress" BU_ LDCME 76;
BA_ "NmStationAddress" BU_ CSDB 54;
BA_ "NmStationAddress" BU_ CSDA 53;
BA_ "OvtpOperationMode" BU_ HCM 1;
BA_ "OvtpEcuAddress" BU_ HCM 113;
BA_ "NodeStartUpTime" BU_ HCM 105;
BA_ "NmStationAddress" BU_ HCM 28;
BA_ "OvtpEcuAddress" BU_ LDCMA 79;
BA_ "Terminator" BU_ LDCMA 1;
BA_ "NodeStartUpTime" BU_ LDCMA 200;
BA_ "NmStationAddress" BU_ LDCMA 79;
BA_ "OvtpEcuAddress" BU_ LDCMB 78;
BA_ "Terminator" BU_ LDCMB 1;
BA_ "NodeStartUpTime" BU_ LDCMB 200;
BA_ "NmStationAddress" BU_ LDCMB 78;
BA_ "GenMsgSendType" BO_ 785 5;
BA_ "GenMsgCycleTime" BO_ 785 100;
BA_ "VFrameFormat" BO_ 785 14;
BA_ "GenMsgSendType" BO_ 769 5;
BA_ "GenMsgCycleTime" BO_ 769 100;
BA_ "VFrameFormat" BO_ 769 14;
BA_ "GenMsgSendType" BO_ 125 0;
BA_ "GenMsgCycleTime" BO_ 125 50;
BA_ "GenMsgDelayTime" BO_ 125 0;
BA_ "VFrameFormat" BO_ 125 14;
BA_ "GenMsgSendType" BO_ 124 0;
BA_ "GenMsgCycleTime" BO_ 124 50;
BA_ "GenMsgDelayTime" BO_ 124 0;
BA_ "VFrameFormat" BO_ 124 14;
BA_ "VFrameFormat" BO_ 1555 14;
BA_ "VFrameFormat" BO_ 1554 14;
BA_ "VFrameFormat" BO_ 1539 14;
BA_ "VFrameFormat" BO_ 1538 14;
BA_ "OvtpPushApplication" BO_ 2612224122 1;
BA_ "GenMsgSendType" BO_ 2612224122 1;
BA_ "TpTxIndex" BO_ 2612224122 464740474;
BA_ "OvtpPushApplication" BO_ 2612224125 1;
BA_ "GenMsgSendType" BO_ 2612224125 1;
BA_ "TpTxIndex" BO_ 2612224125 464740477;
BA_ "DiagResponse" BO_ 2612224125 1;
BA_ "OvtpPushApplication" BO_ 2612127960 1;
BA_ "GenMsgSendType" BO_ 2612127960 1;
BA_ "TpTxIndex" BO_ 2612127960 464644312;
BA_ "OvtpPushApplication" BO_ 2612131032 1;
BA_ "GenMsgSendType" BO_ 2612131032 1;
BA_ "TpTxIndex" BO_ 2612131032 464647384;
BA_ "GenMsgDelayTime" BO_ 2611175546 0;
BA_ "GenMsgSendType" BO_ 2611175546 1;
BA_ "TpTxIndex" BO_ 2611175546 463691898;
BA_ "OvtpPushApplication" BO_ 2611175549 1;
BA_ "GenMsgDelayTime" BO_ 2611175549 0;
BA_ "GenMsgSendType" BO_ 2611175549 1;
BA_ "TpTxIndex" BO_ 2611175549 463691901;
BA_ "GenMsgDelayTime" BO_ 2611079384 0;
BA_ "GenMsgSendType" BO_ 2611079384 1;
BA_ "TpTxIndex" BO_ 2611079384 463595736;
BA_ "GenMsgDelayTime" BO_ 2611082456 0;
BA_ "GenMsgSendType" BO_ 2611082456 1;
BA_ "TpTxIndex" BO_ 2611082456 463598808;
BA_ "GenMsgSendType" BO_ 2610126970 1;
BA_ "TpTxIndex" BO_ 2610126970 462643322;
BA_ "GenMsgSendType" BO_ 2610126973 1;
BA_ "TpTxIndex" BO_ 2610126973 462643325;
BA_ "GenMsgDelayTime" BO_ 2610030808 0;
BA_ "GenMsgSendType" BO_ 2610030808 1;
BA_ "TpTxIndex" BO_ 2610030808 462547160;
BA_ "GenMsgDelayTime" BO_ 2610033880 0;
BA_ "GenMsgSendType" BO_ 2610033880 1;
BA_ "TpTxIndex" BO_ 2610033880 462550232;
BA_ "NetworkInitialization" BO_ 1758 0;
BA_ "GenMsgDelayTime" BO_ 1758 0;
BA_ "GenMsgSendType" BO_ 1758 1;
BA_ "DiagResponse" BO_ 1758 1;
BA_ "GenMsgILSupport" BO_ 1758 0;
BA_ "VFrameFormat" BO_ 1758 14;
BA_ "NetworkInitialization" BO_ 1759 0;
BA_ "GenMsgDelayTime" BO_ 1759 0;
BA_ "GenMsgSendType" BO_ 1759 1;
BA_ "DiagResponse" BO_ 1759 1;
BA_ "GenMsgILSupport" BO_ 1759 0;
BA_ "VFrameFormat" BO_ 1759 14;
BA_ "NetworkInitialization" BO_ 1750 0;
BA_ "GenMsgDelayTime" BO_ 1750 0;
BA_ "GenMsgSendType" BO_ 1750 1;
BA_ "DiagRequest" BO_ 1750 1;
BA_ "GenMsgILSupport" BO_ 1750 0;
BA_ "VFrameFormat" BO_ 1750 14;
BA_ "NetworkInitialization" BO_ 1751 0;
BA_ "GenMsgDelayTime" BO_ 1751 0;
BA_ "GenMsgSendType" BO_ 1751 1;
BA_ "DiagRequest" BO_ 1751 1;
BA_ "GenMsgILSupport" BO_ 1751 0;
BA_ "VFrameFormat" BO_ 1751 14;
BA_ "GenMsgDelayTime" BO_ 123 0;
BA_ "GenMsgCycleTime" BO_ 123 50;
BA_ "GenMsgSendType" BO_ 123 0;
BA_ "VFrameFormat" BO_ 123 14;
BA_ "GenMsgDelayTime" BO_ 122 0;
BA_ "GenMsgCycleTime" BO_ 122 50;
BA_ "GenMsgSendType" BO_ 122 0;
BA_ "VFrameFormat" BO_ 122 14;
BA_ "GenMsgSendType" BO_ 1438 0;
BA_ "GenMsgCycleTime" BO_ 1438 1000;
BA_ "NetworkInitialization" BO_ 1438 0;
BA_ "VFrameFormat" BO_ 1438 14;
BA_ "GenMsgSendType" BO_ 102 5;
BA_ "GenMsgCycleTime" BO_ 102 1000;
BA_ "VFrameFormat" BO_ 102 14;
BA_ "GenMsgCycleTime" BO_ 784 100;
BA_ "GenMsgSendType" BO_ 784 5;
BA_ "VFrameFormat" BO_ 784 14;
BA_ "GenMsgCycleTime" BO_ 768 100;
BA_ "GenMsgSendType" BO_ 768 5;
BA_ "VFrameFormat" BO_ 768 14;
BA_ "VFrameFormat" BO_ 1553 14;
BA_ "VFrameFormat" BO_ 1552 14;
BA_ "VFrameFormat" BO_ 1537 14;
BA_ "VFrameFormat" BO_ 1536 14;
BA_ "OvtpPushApplication" BO_ 2612224078 1;
BA_ "GenMsgSendType" BO_ 2612224078 1;
BA_ "TpTxIndex" BO_ 2612224078 464740430;
BA_ "OvtpPushApplication" BO_ 2612082904 1;
BA_ "GenMsgSendType" BO_ 2612082904 1;
BA_ "TpTxIndex" BO_ 2612082904 464599256;
BA_ "GenMsgDelayTime" BO_ 2611175502 0;
BA_ "GenMsgSendType" BO_ 2611175502 1;
BA_ "TpTxIndex" BO_ 2611175502 463691854;
BA_ "GenMsgDelayTime" BO_ 2611034328 0;
BA_ "GenMsgSendType" BO_ 2611034328 1;
BA_ "TpTxIndex" BO_ 2611034328 463550680;
BA_ "GenMsgSendType" BO_ 2610126926 1;
BA_ "TpTxIndex" BO_ 2610126926 462643278;
BA_ "GenMsgDelayTime" BO_ 2609985752 0;
BA_ "GenMsgSendType" BO_ 2609985752 1;
BA_ "TpTxIndex" BO_ 2609985752 462502104;
BA_ "OvtpPushApplication" BO_ 2612224079 1;
BA_ "GenMsgSendType" BO_ 2612224079 1;
BA_ "TpTxIndex" BO_ 2612224079 464740431;
BA_ "DiagResponse" BO_ 2612224079 1;
BA_ "NetworkInitialization" BO_ 1798 0;
BA_ "GenMsgDelayTime" BO_ 1798 0;
BA_ "GenMsgSendType" BO_ 1798 1;
BA_ "DiagRequest" BO_ 1798 1;
BA_ "GenMsgILSupport" BO_ 1798 0;
BA_ "VFrameFormat" BO_ 1798 14;
BA_ "NetworkInitialization" BO_ 1806 0;
BA_ "GenMsgDelayTime" BO_ 1806 0;
BA_ "GenMsgSendType" BO_ 1806 1;
BA_ "DiagResponse" BO_ 1806 1;
BA_ "GenMsgILSupport" BO_ 1806 0;
BA_ "VFrameFormat" BO_ 1806 14;
BA_ "GenMsgDelayTime" BO_ 800 0;
BA_ "GenMsgCycleTime" BO_ 800 100;
BA_ "GenMsgSendType" BO_ 800 5;
BA_ "VFrameFormat" BO_ 800 14;
BA_ "GenMsgDelayTime" BO_ 121 0;
BA_ "GenMsgCycleTime" BO_ 121 10;
BA_ "GenMsgSendType" BO_ 121 0;
BA_ "VFrameFormat" BO_ 121 14;
BA_ "GenMsgDelayTime" BO_ 120 0;
BA_ "GenMsgCycleTime" BO_ 120 10;
BA_ "GenMsgSendType" BO_ 120 0;
BA_ "VFrameFormat" BO_ 120 14;
BA_ "GenMsgDelayTime" BO_ 119 0;
BA_ "GenMsgCycleTime" BO_ 119 10;
BA_ "GenMsgSendType" BO_ 119 0;
BA_ "VFrameFormat" BO_ 119 14;
BA_ "NetworkInitialization" BO_ 1805 0;
BA_ "GenMsgDelayTime" BO_ 1805 0;
BA_ "GenMsgSendType" BO_ 1805 1;
BA_ "DiagResponse" BO_ 1805 1;
BA_ "GenMsgILSupport" BO_ 1805 0;
BA_ "VFrameFormat" BO_ 1805 14;
BA_ "NetworkInitialization" BO_ 1797 0;
BA_ "GenMsgDelayTime" BO_ 1797 0;
BA_ "GenMsgSendType" BO_ 1797 1;
BA_ "DiagRequest" BO_ 1797 1;
BA_ "GenMsgILSupport" BO_ 1797 0;
BA_ "VFrameFormat" BO_ 1797 14;
BA_ "NetworkInitialization" BO_ 1796 0;
BA_ "GenMsgDelayTime" BO_ 1796 0;
BA_ "GenMsgSendType" BO_ 1796 1;
BA_ "DiagRequest" BO_ 1796 1;
BA_ "GenMsgILSupport" BO_ 1796 0;
BA_ "VFrameFormat" BO_ 1796 14;
BA_ "NetworkInitialization" BO_ 1804 0;
BA_ "GenMsgDelayTime" BO_ 1804 0;
BA_ "GenMsgSendType" BO_ 1804 1;
BA_ "DiagResponse" BO_ 1804 1;
BA_ "GenMsgILSupport" BO_ 1804 0;
BA_ "VFrameFormat" BO_ 1804 14;
BA_ "GenMsgDelayTime" BO_ 2611035352 0;
BA_ "GenMsgSendType" BO_ 2611035352 1;
BA_ "TpTxIndex" BO_ 2611035352 463551704;
BA_ "OvtpPushApplication" BO_ 2612083928 1;
BA_ "GenMsgSendType" BO_ 2612083928 1;
BA_ "TpTxIndex" BO_ 2612083928 464600280;
BA_ "OvtpPushApplication" BO_ 2611175503 1;
BA_ "GenMsgDelayTime" BO_ 2611175503 0;
BA_ "GenMsgSendType" BO_ 2611175503 1;
BA_ "TpTxIndex" BO_ 2611175503 463691855;
BA_ "GenMsgDelayTime" BO_ 2612002008 0;
BA_ "GenMsgSendType" BO_ 2612002008 1;
BA_ "TpTxIndex" BO_ 2612002008 464518360;
BA_ "GenMsgSendType" BO_ 2610126927 1;
BA_ "TpTxIndex" BO_ 2610126927 462643279;
BA_ "GenMsgDelayTime" BO_ 2609986776 0;
BA_ "GenMsgSendType" BO_ 2609986776 1;
BA_ "TpTxIndex" BO_ 2609986776 462503128;
BA_ "GenMsgDelayTime" BO_ 2610953432 0;
BA_ "GenMsgSendType" BO_ 2610953432 1;
BA_ "TpTxIndex" BO_ 2610953432 463469784;
BA_ "GenMsgDelayTime" BO_ 80 0;
BA_ "GenMsgCycleTime" BO_ 80 500;
BA_ "GenMsgSendType" BO_ 80 5;
BA_ "VFrameFormat" BO_ 80 14;
BA_ "NetworkInitialization" BO_ 2015 0;
BA_ "GenMsgDelayTime" BO_ 2015 0;
BA_ "GenMsgSendType" BO_ 2015 1;
BA_ "DiagState" BO_ 2015 1;
BA_ "GenMsgILSupport" BO_ 2015 0;
BA_ "VFrameFormat" BO_ 2015 14;
BA_ "NetworkInitialization" BO_ 1791 0;
BA_ "GenMsgDelayTime" BO_ 1791 0;
BA_ "GenMsgSendType" BO_ 1791 1;
BA_ "DiagResponse" BO_ 1791 1;
BA_ "GenMsgILSupport" BO_ 1791 0;
BA_ "VFrameFormat" BO_ 1791 14;
BA_ "NetworkInitialization" BO_ 1790 0;
BA_ "GenMsgDelayTime" BO_ 1790 0;
BA_ "GenMsgSendType" BO_ 1790 1;
BA_ "DiagResponse" BO_ 1790 1;
BA_ "GenMsgILSupport" BO_ 1790 0;
BA_ "VFrameFormat" BO_ 1790 14;
BA_ "NetworkInitialization" BO_ 1783 0;
BA_ "GenMsgDelayTime" BO_ 1783 0;
BA_ "GenMsgSendType" BO_ 1783 1;
BA_ "DiagRequest" BO_ 1783 1;
BA_ "GenMsgILSupport" BO_ 1783 0;
BA_ "VFrameFormat" BO_ 1783 14;
BA_ "NetworkInitialization" BO_ 1782 0;
BA_ "GenMsgDelayTime" BO_ 1782 0;
BA_ "GenMsgSendType" BO_ 1782 1;
BA_ "DiagRequest" BO_ 1782 1;
BA_ "GenMsgILSupport" BO_ 1782 0;
BA_ "VFrameFormat" BO_ 1782 14;
BA_ "NetworkInitialization" BO_ 1823 0;
BA_ "GenMsgDelayTime" BO_ 1823 0;
BA_ "GenMsgSendType" BO_ 1823 1;
BA_ "DiagResponse" BO_ 1823 1;
BA_ "GenMsgILSupport" BO_ 1823 0;
BA_ "VFrameFormat" BO_ 1823 14;
BA_ "NetworkInitialization" BO_ 1822 0;
BA_ "GenMsgDelayTime" BO_ 1822 0;
BA_ "GenMsgSendType" BO_ 1822 1;
BA_ "DiagResponse" BO_ 1822 1;
BA_ "GenMsgILSupport" BO_ 1822 0;
BA_ "VFrameFormat" BO_ 1822 14;
BA_ "NetworkInitialization" BO_ 1815 0;
BA_ "GenMsgDelayTime" BO_ 1815 0;
BA_ "GenMsgSendType" BO_ 1815 1;
BA_ "DiagRequest" BO_ 1815 1;
BA_ "GenMsgILSupport" BO_ 1815 0;
BA_ "VFrameFormat" BO_ 1815 14;
BA_ "NetworkInitialization" BO_ 1814 0;
BA_ "GenMsgDelayTime" BO_ 1814 0;
BA_ "GenMsgSendType" BO_ 1814 1;
BA_ "DiagRequest" BO_ 1814 1;
BA_ "GenMsgILSupport" BO_ 1814 0;
BA_ "VFrameFormat" BO_ 1814 14;
BA_ "GenMsgDelayTime" BO_ 117 0;
BA_ "GenMsgCycleTime" BO_ 117 50;
BA_ "GenMsgSendType" BO_ 117 0;
BA_ "VFrameFormat" BO_ 117 14;
BA_ "GenMsgDelayTime" BO_ 116 0;
BA_ "GenMsgCycleTime" BO_ 116 50;
BA_ "GenMsgSendType" BO_ 116 0;
BA_ "VFrameFormat" BO_ 116 14;
BA_ "GenMsgDelayTime" BO_ 118 0;
BA_ "GenMsgCycleTime" BO_ 118 30;
BA_ "GenMsgSendType" BO_ 118 0;
BA_ "VFrameFormat" BO_ 118 14;
BA_ "GenMsgDelayTime" BO_ 85 0;
BA_ "GenMsgCycleTime" BO_ 85 10;
BA_ "GenMsgSendType" BO_ 85 0;
BA_ "VFrameFormat" BO_ 85 14;
BA_ "GenMsgDelayTime" BO_ 98 0;
BA_ "GenMsgCycleTime" BO_ 98 30;
BA_ "GenMsgSendType" BO_ 98 0;
BA_ "VFrameFormat" BO_ 98 14;
BA_ "GenMsgDelayTime" BO_ 113 0;
BA_ "GenMsgCycleTime" BO_ 113 30;
BA_ "GenMsgSendType" BO_ 113 0;
BA_ "VFrameFormat" BO_ 113 14;
BA_ "GenMsgDelayTime" BO_ 112 0;
BA_ "GenMsgCycleTime" BO_ 112 30;
BA_ "GenMsgSendType" BO_ 112 0;
BA_ "VFrameFormat" BO_ 112 14;
BA_ "FrameRouting" BO_ 2147484595 "FD3_CAN,0x3B3;";
BA_ "GenSigSendType" SG_ 785 CanMsg311_No_Crc 3;
BA_ "MetaData" SG_ 785 CanMsg311_No_Crc 1;
BA_ "GenSigSendType" SG_ 785 CanMsg311_No_Cnt 3;
BA_ "ContentDependant" SG_ 785 CanMsg311_No_Cnt 1;
BA_ "MetaData" SG_ 785 CanMsg311_No_Cnt 1;
BA_ "U_U611_U625_MY20_Phev_Tx" SG_ 785 TurnLampFrOut_B_Stat2 1;
BA_ "GenSigSendType" SG_ 785 TurnLampFrOut_B_Stat2 3;
BA_ "GenSigStartValue" SG_ 785 HeadLampLoFrOut_B_Stat2 1;
BA_ "GenSigSendType" SG_ 785 HeadLampLoFrOut_B_Stat2 3;
BA_ "GenSigSendType" SG_ 769 CanMsg301_No_Crc 3;
BA_ "MetaData" SG_ 769 CanMsg301_No_Crc 1;
BA_ "GenSigSendType" SG_ 769 CanMsg301_No_Cnt 3;
BA_ "ContentDependant" SG_ 769 CanMsg301_No_Cnt 1;
BA_ "MetaData" SG_ 769 CanMsg301_No_Cnt 1;
BA_ "U_U611_U625_MY20_Phev_Tx" SG_ 769 TurnLampFlOut_B_Stat2 1;
BA_ "GenSigSendType" SG_ 769 TurnLampFlOut_B_Stat2 3;
BA_ "GenSigStartValue" SG_ 769 HeadLampLoFlOut_B_Stat2 1;
BA_ "GenSigSendType" SG_ 769 HeadLampLoFlOut_B_Stat2 3;
BA_ "U_U611_U625_MY20_Phev_Tx" SG_ 125 Hlr_Temp_Stat2 1;
BA_ "U_U611_U625_MY20_Phev_Tx" SG_ 125 Mdule2RightHl_side_Stat 1;
BA_ "U_U611_U625_MY20_Phev_Tx" SG_ 125 Mdule2RightHl_Com_Stat 1;
BA_ "U_U611_U625_MY20_Phev_Tx" SG_ 125 Mdule2Right_MPwr_B_Stat 1;
BA_ "U_U611_U625_MY20_Phev_Tx" SG_ 125 Mdule2Right_LB_Pwr_B_Stat 1;
BA_ "U_U611_U625_MY20_Phev_Tx" SG_ 125 Hlr_SM_Stat2 1;
BA_ "U_U611_U625_MY20_Phev_Tx" SG_ 125 Hlr_SBL_Stat2 1;
BA_ "U_U611_U625_MY20_Phev_Tx" SG_ 125 Hlr_Pixel_Stat2 1;
BA_ "U_U611_U625_MY20_Phev_Tx" SG_ 125 Hlr_Fan_B_Stat2 1;
BA_ "U_U611_U625_MY20_Phev_Tx" SG_ 125 Hlr_DRL_POS_Stat2 1;
BA_ "U_U611_U625_MY20_Phev_Tx" SG_ 125 HeadLghtLvlRght_D_Stat2 1;
BA_ "GenSigStartValue" SG_ 125 HeadLghtLvlRght_D_Stat2 1;
BA_ "U_U611_U625_MY20_Phev_Tx" SG_ 125 HeadLghtLvlRght_No_Stat2 1;
BA_ "U_U611_U625_MY20_Phev_Tx" SG_ 125 Mdule2RightFail_B_Stat 1;
BA_ "U_U611_U625_MY20_Phev_Tx" SG_ 125 Mdule2RightConfg_B_Stat 1;
BA_ "U_U611_U625_MY20_Phev_Tx" SG_ 124 HeadLghtLvlLeft_No_Stat2 1;
BA_ "U_U611_U625_MY20_Phev_Tx" SG_ 124 Hll_Temp_Stat2 1;
BA_ "U_U611_U625_MY20_Phev_Tx" SG_ 124 Mdule2LeftHl_side_Stat 1;
BA_ "U_U611_U625_MY20_Phev_Tx" SG_ 124 Mdule2LeftHl_Com_Stat 1;
BA_ "U_U611_U625_MY20_Phev_Tx" SG_ 124 Mdule2Left_MPwr_B_Stat 1;
BA_ "U_U611_U625_MY20_Phev_Tx" SG_ 124 Mdule2Left_LB_Pwr_B_Stat 1;
BA_ "U_U611_U625_MY20_Phev_Tx" SG_ 124 Hll_SM_Stat2 1;
BA_ "U_U611_U625_MY20_Phev_Tx" SG_ 124 Hll_SBL_Stat2 1;
BA_ "U_U611_U625_MY20_Phev_Tx" SG_ 124 Hll_Pixel_Stat2 1;
BA_ "U_U611_U625_MY20_Phev_Tx" SG_ 124 Hll_Fan_B_Stat2 1;
BA_ "U_U611_U625_MY20_Phev_Tx" SG_ 124 Hll_DRL_POS_Stat2 1;
BA_ "U_U611_U625_MY20_Phev_Tx" SG_ 124 HeadLghtLvlLeft_D_Stat2 1;
BA_ "GenSigStartValue" SG_ 124 HeadLghtLvlLeft_D_Stat2 1;
BA_ "U_U611_U625_MY20_Phev_Tx" SG_ 124 Mdule2LeftFail_B_Stat 1;
BA_ "U_U611_U625_MY20_Phev_Tx" SG_ 124 Mdule2LeftConfg_B_Stat 1;
BA_ "GenSigSendType" SG_ 1555 XCP_TSTRtoLDCMD 3;
BA_ "GenSigSendType" SG_ 1554 XCP_TSTRtoLDCMC 3;
BA_ "GenSigSendType" SG_ 1539 XCP_LDCMDtoTSTR 3;
BA_ "GenSigSendType" SG_ 1538 XCP_LDCMCtoTSTR 3;
BA_ "GenSigTimeoutTime_X_LDMFL1" SG_ 2612224122 PARSEDPushLDCMDtoGWM_ECG 0;
BA_ "GenSigTimeoutTime_X_LDMFR1" SG_ 2612224122 PARSEDPushLDCMDtoGWM_ECG 0;
BA_ "GenSigTimeoutTime_HCM_SUBNET" SG_ 2612224122 PARSEDPushLDCMDtoGWM_ECG 0;
BA_ "GenSigSendType" SG_ 2612224122 PARSEDPushLDCMDtoGWM_ECG 3;
BA_ "GenSigTimeoutTime_X_LDMFL1" SG_ 2612224125 PARSEDPushLDCMCtoGWM_ECG 0;
BA_ "GenSigTimeoutTime_X_LDMFR1" SG_ 2612224125 PARSEDPushLDCMCtoGWM_ECG 0;
BA_ "GenSigTimeoutTime_HCM_SUBNET" SG_ 2612224125 PARSEDPushLDCMCtoGWM_ECG 0;
BA_ "GenSigSendType" SG_ 2612224125 PARSEDPushLDCMCtoGWM_ECG 3;
BA_ "GenSigTimeoutTime_X_LDMFL1" SG_ 2612127960 PARSEDPushFcGWM_ECGtoLDCMD 0;
BA_ "GenSigTimeoutTime_X_LDMFR1" SG_ 2612127960 PARSEDPushFcGWM_ECGtoLDCMD 0;
BA_ "GenSigTimeoutTime_HCM_SUBNET" SG_ 2612127960 PARSEDPushFcGWM_ECGtoLDCMD 0;
BA_ "GenSigSendType" SG_ 2612127960 PARSEDPushFcGWM_ECGtoLDCMD 3;
BA_ "GenSigTimeoutTime_X_LDMFL1" SG_ 2612131032 PARSEDPushFcGWM_ECGtoLDCMC 0;
BA_ "GenSigTimeoutTime_X_LDMFR1" SG_ 2612131032 PARSEDPushFcGWM_ECGtoLDCMC 0;
BA_ "GenSigTimeoutTime_HCM_SUBNET" SG_ 2612131032 PARSEDPushFcGWM_ECGtoLDCMC 0;
BA_ "GenSigSendType" SG_ 2612131032 PARSEDPushFcGWM_ECGtoLDCMC 3;
BA_ "GenSigTimeoutTime_X_LDMFL1" SG_ 2611175546 PARSEDPhysLDCMDtoGWM_ECG 0;
BA_ "GenSigTimeoutTime_X_LDMFR1" SG_ 2611175546 PARSEDPhysLDCMDtoGWM_ECG 0;
BA_ "GenSigTimeoutTime_HCM_SUBNET" SG_ 2611175546 PARSEDPhysLDCMDtoGWM_ECG 0;
BA_ "GenSigSendType" SG_ 2611175546 PARSEDPhysLDCMDtoGWM_ECG 3;
BA_ "GenSigTimeoutTime_X_LDMFL1" SG_ 2611175549 PARSEDPhysLDCMCtoGWM_ECG 0;
BA_ "GenSigTimeoutTime_X_LDMFR1" SG_ 2611175549 PARSEDPhysLDCMCtoGWM_ECG 0;
BA_ "GenSigTimeoutTime_HCM_SUBNET" SG_ 2611175549 PARSEDPhysLDCMCtoGWM_ECG 0;
BA_ "GenSigSendType" SG_ 2611175549 PARSEDPhysLDCMCtoGWM_ECG 3;
BA_ "GenSigTimeoutTime_X_LDMFL1" SG_ 2611079384 PARSEDPhysGWM_ECGtoLDCMD 0;
BA_ "GenSigTimeoutTime_X_LDMFR1" SG_ 2611079384 PARSEDPhysGWM_ECGtoLDCMD 0;
BA_ "GenSigTimeoutTime_HCM_SUBNET" SG_ 2611079384 PARSEDPhysGWM_ECGtoLDCMD 0;
BA_ "GenSigSendType" SG_ 2611079384 PARSEDPhysGWM_ECGtoLDCMD 3;
BA_ "GenSigTimeoutTime_X_LDMFL1" SG_ 2611082456 PARSEDPhysGWM_ECGtoLDCMC 0;
BA_ "GenSigTimeoutTime_X_LDMFR1" SG_ 2611082456 PARSEDPhysGWM_ECGtoLDCMC 0;
BA_ "GenSigTimeoutTime_HCM_SUBNET" SG_ 2611082456 PARSEDPhysGWM_ECGtoLDCMC 0;
BA_ "GenSigSendType" SG_ 2611082456 PARSEDPhysGWM_ECGtoLDCMC 3;
BA_ "GenSigTimeoutTime_X_LDMFL1" SG_ 2610126970 OTAPhysLDCMDtoGWM_ECG 0;
BA_ "GenSigTimeoutTime_X_LDMFR1" SG_ 2610126970 OTAPhysLDCMDtoGWM_ECG 0;
BA_ "GenSigTimeoutTime_HCM_SUBNET" SG_ 2610126970 OTAPhysLDCMDtoGWM_ECG 0;
BA_ "GenSigSendType" SG_ 2610126970 OTAPhysLDCMDtoGWM_ECG 3;
BA_ "GenSigTimeoutTime_X_LDMFL1" SG_ 2610126973 OTAPhysLDCMCtoGWM_ECG 0;
BA_ "GenSigTimeoutTime_X_LDMFR1" SG_ 2610126973 OTAPhysLDCMCtoGWM_ECG 0;
BA_ "GenSigTimeoutTime_HCM_SUBNET" SG_ 2610126973 OTAPhysLDCMCtoGWM_ECG 0;
BA_ "GenSigSendType" SG_ 2610126973 OTAPhysLDCMCtoGWM_ECG 3;
BA_ "GenSigTimeoutTime_X_LDMFL1" SG_ 2610030808 OTAPhysGWM_ECGtoLDCMD 0;
BA_ "GenSigTimeoutTime_X_LDMFR1" SG_ 2610030808 OTAPhysGWM_ECGtoLDCMD 0;
BA_ "GenSigTimeoutTime_HCM_SUBNET" SG_ 2610030808 OTAPhysGWM_ECGtoLDCMD 0;
BA_ "GenSigSendType" SG_ 2610030808 OTAPhysGWM_ECGtoLDCMD 3;
BA_ "GenSigTimeoutTime_X_LDMFL1" SG_ 2610033880 OTAPhysGWM_ECGtoLDCMC 0;
BA_ "GenSigTimeoutTime_X_LDMFR1" SG_ 2610033880 OTAPhysGWM_ECGtoLDCMC 0;
BA_ "GenSigTimeoutTime_HCM_SUBNET" SG_ 2610033880 OTAPhysGWM_ECGtoLDCMC 0;
BA_ "GenSigSendType" SG_ 2610033880 OTAPhysGWM_ECGtoLDCMC 3;
BA_ "GenSigSendType" SG_ 1758 TesterPhysicalResLDCMD 3;
BA_ "GenSigSendType" SG_ 1759 TesterPhysicalResLDCMC 3;
BA_ "GenSigSendType" SG_ 1750 TesterPhysicalReqLDCMD 3;
BA_ "GenSigSendType" SG_ 1751 TesterPhysicalReqLDCMC 3;
BA_ "GenSigStartValue" SG_ 123 TailLghtAnmtnRight_D_Stat 1;
BA_ "GenSigStartValue" SG_ 122 TailLghtAnmtnLeft_D_Stat 1;
BA_ "GenSigStartValue" SG_ 1438 GWM_GWOnBoardTester 255;
BA_ "GenSigStartValue" SG_ 1438 GWM_GWNMProxy 255;
BA_ "GenSigStartValue" SG_ 1438 GWM_AutoSarNMReserved4 255;
BA_ "GenSigStartValue" SG_ 1438 GWM_AutoSarNMReserved3 255;
BA_ "GenSigStartValue" SG_ 1438 GWM_AutoSarNMReserved2 255;
BA_ "GenSigStartValue" SG_ 1438 GWM_AutoSarNMReserved1 255;
BA_ "GenSigStartValue" SG_ 1438 GWM_AutoSarNMNodeId 158;
BA_ "GenSigSendType" SG_ 102 Hbm6TrnstnRight_An_Rq 3;
BA_ "GenSigSendType" SG_ 102 Hbm6TrnstnLeft_An_Rq 3;
BA_ "U_U611_U625_MY20_Phev_Tx" SG_ 102 Hbm6RightLghtRigh_An_Rq 1;
BA_ "GenSigStartValue" SG_ 102 Hbm6RightLghtRigh_An_Rq 256;
BA_ "GenSigSendType" SG_ 102 Hbm6RightLghtRigh_An_Rq 3;
BA_ "U_U611_U625_MY20_Phev_Tx" SG_ 102 Hbm6RightLghtLeft_An_Rq 1;
BA_ "GenSigStartValue" SG_ 102 Hbm6RightLghtLeft_An_Rq 256;
BA_ "GenSigSendType" SG_ 102 Hbm6RightLghtLeft_An_Rq 3;
BA_ "GenSigSendType" SG_ 102 Hbm6Ramping_T_Rq 3;
BA_ "U_U611_U625_MY20_Phev_Tx" SG_ 102 Hbm6LeftLghtRight_An_Rq 1;
BA_ "GenSigStartValue" SG_ 102 Hbm6LeftLghtRight_An_Rq 256;
BA_ "GenSigSendType" SG_ 102 Hbm6LeftLghtRight_An_Rq 3;
BA_ "U_U611_U625_MY20_Phev_Tx" SG_ 102 Hbm6LeftLghtLeft_An_Rq 1;
BA_ "GenSigStartValue" SG_ 102 Hbm6LeftLghtLeft_An_Rq 256;
BA_ "GenSigSendType" SG_ 102 Hbm6LeftLghtLeft_An_Rq 3;
BA_ "U_U611_U625_MY20_Phev_Tx" SG_ 102 Hbm6BrdrTop_An_Rq 1;
BA_ "GenSigStartValue" SG_ 102 Hbm6BrdrTop_An_Rq 50;
BA_ "GenSigSendType" SG_ 102 Hbm6BrdrTop_An_Rq 3;
BA_ "U_U611_U625_MY20_Phev_Tx" SG_ 102 Hbm6BrdrBottom_An_Rq 1;
BA_ "GenSigStartValue" SG_ 102 Hbm6BrdrBottom_An_Rq 50;
BA_ "GenSigSendType" SG_ 102 Hbm6BrdrBottom_An_Rq 3;
BA_ "GenSigSendType" SG_ 102 Hbm5TrnstnRight_An_Rq 3;
BA_ "GenSigSendType" SG_ 102 Hbm5TrnstnLeft_An_Rq 3;
BA_ "U_U611_U625_MY20_Phev_Tx" SG_ 102 Hbm5RightLghtRigh_An_Rq 1;
BA_ "GenSigStartValue" SG_ 102 Hbm5RightLghtRigh_An_Rq 256;
BA_ "GenSigSendType" SG_ 102 Hbm5RightLghtRigh_An_Rq 3;
BA_ "U_U611_U625_MY20_Phev_Tx" SG_ 102 Hbm5RightLghtLeft_An_Rq 1;
BA_ "GenSigStartValue" SG_ 102 Hbm5RightLghtLeft_An_Rq 256;
BA_ "GenSigSendType" SG_ 102 Hbm5RightLghtLeft_An_Rq 3;
BA_ "GenSigSendType" SG_ 102 Hbm5Ramping_T_Rq 3;
BA_ "U_U611_U625_MY20_Phev_Tx" SG_ 102 Hbm5LeftLghtRight_An_Rq 1;
BA_ "GenSigStartValue" SG_ 102 Hbm5LeftLghtRight_An_Rq 256;
BA_ "GenSigSendType" SG_ 102 Hbm5LeftLghtRight_An_Rq 3;
BA_ "U_U611_U625_MY20_Phev_Tx" SG_ 102 Hbm5LeftLghtLeft_An_Rq 1;
BA_ "GenSigStartValue" SG_ 102 Hbm5LeftLghtLeft_An_Rq 256;
BA_ "GenSigSendType" SG_ 102 Hbm5LeftLghtLeft_An_Rq 3;
BA_ "U_U611_U625_MY20_Phev_Tx" SG_ 102 Hbm5BrdrTop_An_Rq 1;
BA_ "GenSigStartValue" SG_ 102 Hbm5BrdrTop_An_Rq 50;
BA_ "GenSigSendType" SG_ 102 Hbm5BrdrTop_An_Rq 3;
BA_ "U_U611_U625_MY20_Phev_Tx" SG_ 102 Hbm5BrdrBottom_An_Rq 1;
BA_ "GenSigStartValue" SG_ 102 Hbm5BrdrBottom_An_Rq 50;
BA_ "GenSigSendType" SG_ 102 Hbm5BrdrBottom_An_Rq 3;
BA_ "GenSigSendType" SG_ 102 Hbm4TrnstnRight_An_Rq 3;
BA_ "GenSigSendType" SG_ 102 Hbm4TrnstnLeft_An_Rq 3;
BA_ "U_U611_U625_MY20_Phev_Tx" SG_ 102 Hbm4RightLghtRigh_An_Rq 1;
BA_ "GenSigStartValue" SG_ 102 Hbm4RightLghtRigh_An_Rq 256;
BA_ "GenSigSendType" SG_ 102 Hbm4RightLghtRigh_An_Rq 3;
BA_ "U_U611_U625_MY20_Phev_Tx" SG_ 102 Hbm4RightLghtLeft_An_Rq 1;
BA_ "GenSigStartValue" SG_ 102 Hbm4RightLghtLeft_An_Rq 256;
BA_ "GenSigSendType" SG_ 102 Hbm4RightLghtLeft_An_Rq 3;
BA_ "GenSigSendType" SG_ 102 Hbm4Ramping_T_Rq 3;
BA_ "U_U611_U625_MY20_Phev_Tx" SG_ 102 Hbm4LeftLghtRight_An_Rq 1;
BA_ "GenSigStartValue" SG_ 102 Hbm4LeftLghtRight_An_Rq 256;
BA_ "GenSigSendType" SG_ 102 Hbm4LeftLghtRight_An_Rq 3;
BA_ "U_U611_U625_MY20_Phev_Tx" SG_ 102 Hbm4LeftLghtLeft_An_Rq 1;
BA_ "GenSigStartValue" SG_ 102 Hbm4LeftLghtLeft_An_Rq 256;
BA_ "GenSigSendType" SG_ 102 Hbm4LeftLghtLeft_An_Rq 3;
BA_ "U_U611_U625_MY20_Phev_Tx" SG_ 102 Hbm4BrdrTop_An_Rq 1;
BA_ "GenSigStartValue" SG_ 102 Hbm4BrdrTop_An_Rq 50;
BA_ "GenSigSendType" SG_ 102 Hbm4BrdrTop_An_Rq 3;
BA_ "U_U611_U625_MY20_Phev_Tx" SG_ 102 Hbm4BrdrBottom_An_Rq 1;
BA_ "GenSigStartValue" SG_ 102 Hbm4BrdrBottom_An_Rq 50;
BA_ "GenSigSendType" SG_ 102 Hbm4BrdrBottom_An_Rq 3;
BA_ "GenSigSendType" SG_ 102 Hbm3TrnstnRight_An_Rq 3;
BA_ "GenSigSendType" SG_ 102 Hbm3TrnstnLeft_An_Rq 3;
BA_ "U_U611_U625_MY20_Phev_Tx" SG_ 102 Hbm3RightLghtRigh_An_Rq 1;
BA_ "GenSigStartValue" SG_ 102 Hbm3RightLghtRigh_An_Rq 256;
BA_ "GenSigSendType" SG_ 102 Hbm3RightLghtRigh_An_Rq 3;
BA_ "U_U611_U625_MY20_Phev_Tx" SG_ 102 Hbm3RightLghtLeft_An_Rq 1;
BA_ "GenSigStartValue" SG_ 102 Hbm3RightLghtLeft_An_Rq 256;
BA_ "GenSigSendType" SG_ 102 Hbm3RightLghtLeft_An_Rq 3;
BA_ "GenSigSendType" SG_ 102 Hbm3Ramping_T_Rq 3;
BA_ "U_U611_U625_MY20_Phev_Tx" SG_ 102 Hbm3LeftLghtRight_An_Rq 1;
BA_ "GenSigStartValue" SG_ 102 Hbm3LeftLghtRight_An_Rq 256;
BA_ "GenSigSendType" SG_ 102 Hbm3LeftLghtRight_An_Rq 3;
BA_ "U_U611_U625_MY20_Phev_Tx" SG_ 102 Hbm3BrdrTop_An_Rq 1;
BA_ "GenSigStartValue" SG_ 102 Hbm3BrdrTop_An_Rq 50;
BA_ "GenSigSendType" SG_ 102 Hbm3BrdrTop_An_Rq 3;
BA_ "U_U611_U625_MY20_Phev_Tx" SG_ 102 Hbm3BrdrBottom_An_Rq 1;
BA_ "GenSigStartValue" SG_ 102 Hbm3BrdrBottom_An_Rq 50;
BA_ "GenSigSendType" SG_ 102 Hbm3BrdrBottom_An_Rq 3;
BA_ "U_U611_U625_MY20_Phev_Tx" SG_ 102 Hbm2BrdrBottom_An_Rq 1;
BA_ "GenSigStartValue" SG_ 102 Hbm2BrdrBottom_An_Rq 50;
BA_ "GenSigSendType" SG_ 102 Hbm2BrdrBottom_An_Rq 3;
BA_ "GenSigStartValue" SG_ 102 Hbm1BrdrBottom_An_Rq 50;
BA_ "U_U611_U625_MY20_Phev_Tx" SG_ 102 Hbm1BrdrBottom_An_Rq 1;
BA_ "GenSigSendType" SG_ 102 Hbm1BrdrBottom_An_Rq 3;
BA_ "U_U611_U625_MY20_Phev_Tx" SG_ 102 Hbm2BrdrTop_An_Rq 1;
BA_ "GenSigStartValue" SG_ 102 Hbm2BrdrTop_An_Rq 50;
BA_ "GenSigSendType" SG_ 102 Hbm2BrdrTop_An_Rq 3;
BA_ "GenSigStartValue" SG_ 102 Hbm1BrdrTop_An_Rq 50;
BA_ "U_U611_U625_MY20_Phev_Tx" SG_ 102 Hbm1BrdrTop_An_Rq 1;
BA_ "GenSigSendType" SG_ 102 Hbm1BrdrTop_An_Rq 3;
BA_ "GenSigSendType" SG_ 102 Hbm2TrnstnRight_An_Rq 3;
BA_ "GenSigSendType" SG_ 102 Hbm1TrnstnRight_An_Rq 3;
BA_ "U_U611_U625_MY20_Phev_Tx" SG_ 102 Hbm2RightLghtRigh_An_Rq 1;
BA_ "GenSigStartValue" SG_ 102 Hbm2RightLghtRigh_An_Rq 256;
BA_ "GenSigSendType" SG_ 102 Hbm2RightLghtRigh_An_Rq 3;
BA_ "GenSigStartValue" SG_ 102 Hbm1RightLghtRigh_An_Rq 256;
BA_ "U_U611_U625_MY20_Phev_Tx" SG_ 102 Hbm1RightLghtRigh_An_Rq 1;
BA_ "GenSigSendType" SG_ 102 Hbm1RightLghtRigh_An_Rq 3;
BA_ "U_U611_U625_MY20_Phev_Tx" SG_ 102 Hbm2LeftLghtRight_An_Rq 1;
BA_ "GenSigStartValue" SG_ 102 Hbm2LeftLghtRight_An_Rq 256;
BA_ "GenSigSendType" SG_ 102 Hbm2LeftLghtRight_An_Rq 3;
BA_ "GenSigStartValue" SG_ 102 Hbm1LeftLghtRight_An_Rq 256;
BA_ "U_U611_U625_MY20_Phev_Tx" SG_ 102 Hbm1LeftLghtRight_An_Rq 1;
BA_ "GenSigSendType" SG_ 102 Hbm1LeftLghtRight_An_Rq 3;
BA_ "GenSigSendType" SG_ 102 Hbm2TrnstnLeft_An_Rq 3;
BA_ "GenSigSendType" SG_ 102 Hbm1TrnstnLeft_An_Rq 3;
BA_ "U_U611_U625_MY20_Phev_Tx" SG_ 102 Hbm2RightLghtLeft_An_Rq 1;
BA_ "GenSigStartValue" SG_ 102 Hbm2RightLghtLeft_An_Rq 256;
BA_ "GenSigSendType" SG_ 102 Hbm2RightLghtLeft_An_Rq 3;
BA_ "GenSigStartValue" SG_ 102 Hbm1RightLghtLeft_An_Rq 256;
BA_ "U_U611_U625_MY20_Phev_Tx" SG_ 102 Hbm1RightLghtLeft_An_Rq 1;
BA_ "GenSigSendType" SG_ 102 Hbm1RightLghtLeft_An_Rq 3;
BA_ "U_U611_U625_MY20_Phev_Tx" SG_ 102 Hbm3LeftLghtLeft_An_Rq 1;
BA_ "GenSigStartValue" SG_ 102 Hbm3LeftLghtLeft_An_Rq 256;
BA_ "GenSigSendType" SG_ 102 Hbm3LeftLghtLeft_An_Rq 3;
BA_ "U_U611_U625_MY20_Phev_Tx" SG_ 102 Hbm2LeftLghtLeft_An_Rq 1;
BA_ "GenSigStartValue" SG_ 102 Hbm2LeftLghtLeft_An_Rq 256;
BA_ "GenSigSendType" SG_ 102 Hbm2LeftLghtLeft_An_Rq 3;
BA_ "GenSigStartValue" SG_ 102 Hbm1LeftLghtLeft_An_Rq 256;
BA_ "U_U611_U625_MY20_Phev_Tx" SG_ 102 Hbm1LeftLghtLeft_An_Rq 1;
BA_ "GenSigSendType" SG_ 102 Hbm1LeftLghtLeft_An_Rq 3;
BA_ "GenSigSendType" SG_ 102 Hbm2Ramping_T_Rq 3;
BA_ "GenSigSendType" SG_ 102 Hbm1Ramping_T_Rq 3;
BA_ "GenSigSendType" SG_ 102 Hbm6Mde_D_Rq 3;
BA_ "GenSigSendType" SG_ 102 Hbm5Mde_D_Rq 3;
BA_ "GenSigSendType" SG_ 102 Hbm4Mde_D_Rq 3;
BA_ "GenSigSendType" SG_ 102 Hbm3Mde_D_Rq 3;
BA_ "GenSigSendType" SG_ 102 Hbm2Mde_D_Rq 3;
BA_ "GenSigSendType" SG_ 102 Hbm1Mde_D_Rq 3;
BA_ "GenSigSendType" SG_ 102 HeadLghtHi_T_Rq 3;
BA_ "GenSigSendType" SG_ 102 HeadLghtHi_D_Rq 3;
BA_ "U_U611_U625_MY20_Phev_Tx" SG_ 784 TurnLampFrOut_B_Stat 1;
BA_ "GenSigSendType" SG_ 784 TurnLampFrOut_B_Stat 3;
BA_ "GenSigStartValue" SG_ 784 HeadLampLoFrOut_B_Stat 1;
BA_ "GenSigSendType" SG_ 784 HeadLampLoFrOut_B_Stat 3;
BA_ "MetaData" SG_ 784 CanMsg310_No_Crc 1;
BA_ "GenSigSendType" SG_ 784 CanMsg310_No_Crc 3;
BA_ "MetaData" SG_ 784 CanMsg310_No_Cnt 1;
BA_ "ContentDependant" SG_ 784 CanMsg310_No_Cnt 1;
BA_ "GenSigSendType" SG_ 784 CanMsg310_No_Cnt 3;
BA_ "U_U611_U625_MY20_Phev_Tx" SG_ 768 TurnLampFlOut_B_Stat 1;
BA_ "GenSigSendType" SG_ 768 TurnLampFlOut_B_Stat 3;
BA_ "GenSigStartValue" SG_ 768 HeadLampLoFlOut_B_Stat 1;
BA_ "GenSigSendType" SG_ 768 HeadLampLoFlOut_B_Stat 3;
BA_ "MetaData" SG_ 768 CanMsg300_No_Crc 1;
BA_ "GenSigSendType" SG_ 768 CanMsg300_No_Crc 3;
BA_ "MetaData" SG_ 768 CanMsg300_No_Cnt 1;
BA_ "ContentDependant" SG_ 768 CanMsg300_No_Cnt 1;
BA_ "GenSigSendType" SG_ 768 CanMsg300_No_Cnt 3;
BA_ "GenSigSendType" SG_ 1553 XCP_TSTRtoLDCMB 3;
BA_ "GenSigSendType" SG_ 1552 XCP_TSTRtoLDCMA 3;
BA_ "GenSigSendType" SG_ 1537 XCP_LDCMBtoTSTR 3;
BA_ "GenSigSendType" SG_ 1536 XCP_LDCMAtoTSTR 3;
BA_ "GenSigTimeoutTime_X_LDMFL1" SG_ 2612224078 PARSEDPushLDCMBtoGWM_ECG 0;
BA_ "GenSigTimeoutTime_X_LDMFR1" SG_ 2612224078 PARSEDPushLDCMBtoGWM_ECG 0;
BA_ "GenSigTimeoutTime_HCM_SUBNET" SG_ 2612224078 PARSEDPushLDCMBtoGWM_ECG 0;
BA_ "GenSigSendType" SG_ 2612224078 PARSEDPushLDCMBtoGWM_ECG 3;
BA_ "GenSigTimeoutTime_X_LDMFL1" SG_ 2612082904 PARSEDPushFcGWM_ECGtoLDCMB 0;
BA_ "GenSigTimeoutTime_X_LDMFR1" SG_ 2612082904 PARSEDPushFcGWM_ECGtoLDCMB 0;
BA_ "GenSigTimeoutTime_HCM_SUBNET" SG_ 2612082904 PARSEDPushFcGWM_ECGtoLDCMB 0;
BA_ "GenSigSendType" SG_ 2612082904 PARSEDPushFcGWM_ECGtoLDCMB 3;
BA_ "GenSigTimeoutTime_X_LDMFL1" SG_ 2611175502 PARSEDPhysLDCMBtoGWM_ECG 0;
BA_ "GenSigTimeoutTime_X_LDMFR1" SG_ 2611175502 PARSEDPhysLDCMBtoGWM_ECG 0;
BA_ "GenSigTimeoutTime_HCM_SUBNET" SG_ 2611175502 PARSEDPhysLDCMBtoGWM_ECG 0;
BA_ "GenSigSendType" SG_ 2611175502 PARSEDPhysLDCMBtoGWM_ECG 3;
BA_ "GenSigTimeoutTime_X_LDMFL1" SG_ 2611034328 PARSEDPhysGWM_ECGtoLDCMB 0;
BA_ "GenSigTimeoutTime_X_LDMFR1" SG_ 2611034328 PARSEDPhysGWM_ECGtoLDCMB 0;
BA_ "GenSigTimeoutTime_HCM_SUBNET" SG_ 2611034328 PARSEDPhysGWM_ECGtoLDCMB 0;
BA_ "GenSigSendType" SG_ 2611034328 PARSEDPhysGWM_ECGtoLDCMB 3;
BA_ "GenSigTimeoutTime_X_LDMFL1" SG_ 2610126926 OTAPhysLDCMBtoGWM_ECG 0;
BA_ "GenSigTimeoutTime_X_LDMFR1" SG_ 2610126926 OTAPhysLDCMBtoGWM_ECG 0;
BA_ "GenSigTimeoutTime_HCM_SUBNET" SG_ 2610126926 OTAPhysLDCMBtoGWM_ECG 0;
BA_ "GenSigSendType" SG_ 2610126926 OTAPhysLDCMBtoGWM_ECG 3;
BA_ "GenSigTimeoutTime_X_LDMFL1" SG_ 2609985752 OTAPhysGWM_ECGtoLDCMB 0;
BA_ "GenSigTimeoutTime_X_LDMFR1" SG_ 2609985752 OTAPhysGWM_ECGtoLDCMB 0;
BA_ "GenSigTimeoutTime_HCM_SUBNET" SG_ 2609985752 OTAPhysGWM_ECGtoLDCMB 0;
BA_ "GenSigSendType" SG_ 2609985752 OTAPhysGWM_ECGtoLDCMB 3;
BA_ "GenSigTimeoutTime_X_LDMFL1" SG_ 2612224079 PARSEDPushLDCMAtoGWM_ECG 0;
BA_ "GenSigTimeoutTime_X_LDMFR1" SG_ 2612224079 PARSEDPushLDCMAtoGWM_ECG 0;
BA_ "GenSigTimeoutTime_HCM_SUBNET" SG_ 2612224079 PARSEDPushLDCMAtoGWM_ECG 0;
BA_ "GenSigSendType" SG_ 2612224079 PARSEDPushLDCMAtoGWM_ECG 3;
BA_ "GenSigSendType" SG_ 1798 TesterPhysicalReqDev 3;
BA_ "GenSigSendType" SG_ 1806 TesterPhysicalResDev 3;
BA_ "MetaData" SG_ 800 CanMsg320_No_Crc 1;
BA_ "GenSigSendType" SG_ 800 CanMsg320_No_Crc 3;
BA_ "MetaData" SG_ 800 CanMsg320_No_Cnt 1;
BA_ "ContentDependant" SG_ 800 CanMsg320_No_Cnt 1;
BA_ "GenSigSendType" SG_ 800 CanMsg320_No_Cnt 3;
BA_ "GenSigSendType" SG_ 800 TurnLghtRight_D_Rq 3;
BA_ "GenSigSendType" SG_ 800 TurnLghtLeft_D_Rq 3;
BA_ "GenSigSendType" SG_ 800 HeadLampLoFrOn_B_Stat 3;
BA_ "GenSigSendType" SG_ 800 HeadLampLoFlOn_B_Stat 3;
BA_ "U_U611_U625_MY20_Phev_Tx" SG_ 121 DblMtrRight_Motion_B_Stat 1;
BA_ "U_U611_U625_MY20_Phev_Tx" SG_ 121 SwvlTrgtRight_An_D_Stat 1;
BA_ "GenSigStartValue" SG_ 121 SwvlTrgtRight_An_D_Stat 875;
BA_ "U_U611_U625_MY20_Phev_Tx" SG_ 121 HeadLghtDblRght_D_Stat 1;
BA_ "U_U611_U625_MY20_Phev_Tx" SG_ 120 DblMtrLeft_Motion_B_Stat 1;
BA_ "U_U611_U625_MY20_Phev_Tx" SG_ 120 SwvlTrgtLeft_An_D_Stat 1;
BA_ "GenSigStartValue" SG_ 120 SwvlTrgtLeft_An_D_Stat 875;
BA_ "U_U611_U625_MY20_Phev_Tx" SG_ 120 HeadLghtDbllLeft_D_Stat 1;
BA_ "U_U611_U625_MY20_Phev_Tx" SG_ 119 HeadLghtDblRghtRef_D_Rq 1;
BA_ "U_U611_U625_MY20_Phev_Tx" SG_ 119 HeadLghtDblLeftRef_D_Rq 1;
BA_ "U_U611_U625_MY20_Phev_Tx" SG_ 119 MtrSwvlTrgtRight_An_Rq 1;
BA_ "GenSigStartValue" SG_ 119 MtrSwvlTrgtRight_An_Rq 875;
BA_ "U_U611_U625_MY20_Phev_Tx" SG_ 119 MtrSwvlTrgtLeft_An_Rq 1;
BA_ "GenSigStartValue" SG_ 119 MtrSwvlTrgtLeft_An_Rq 875;
BA_ "GenSigSendType" SG_ 1805 TesterPhysicalResCDSB 3;
BA_ "GenSigSendType" SG_ 1797 TesterPhysicalReqCDSB 3;
BA_ "GenSigSendType" SG_ 1796 TesterPhysicalReqCDSA 3;
BA_ "GenSigSendType" SG_ 1804 TesterPhysicalResCDSA 3;
BA_ "GenSigTimeoutTime_X_LDMFL1" SG_ 2611035352 PARSEDPhysGWM_ECGtoLDCMA 0;
BA_ "GenSigTimeoutTime_X_LDMFR1" SG_ 2611035352 PARSEDPhysGWM_ECGtoLDCMA 0;
BA_ "GenSigTimeoutTime_HCM_SUBNET" SG_ 2611035352 PARSEDPhysGWM_ECGtoLDCMA 0;
BA_ "GenSigSendType" SG_ 2611035352 PARSEDPhysGWM_ECGtoLDCMA 3;
BA_ "GenSigTimeoutTime_X_LDMFL1" SG_ 2612083928 PARSEDPushFcGWM_ECGtoLDCMA 0;
BA_ "GenSigTimeoutTime_X_LDMFR1" SG_ 2612083928 PARSEDPushFcGWM_ECGtoLDCMA 0;
BA_ "GenSigTimeoutTime_HCM_SUBNET" SG_ 2612083928 PARSEDPushFcGWM_ECGtoLDCMA 0;
BA_ "GenSigSendType" SG_ 2612083928 PARSEDPushFcGWM_ECGtoLDCMA 3;
BA_ "GenSigTimeoutTime_X_LDMFL1" SG_ 2611175503 PARSEDPhysLDCMAtoGWM_ECG 0;
BA_ "GenSigTimeoutTime_X_LDMFR1" SG_ 2611175503 PARSEDPhysLDCMAtoGWM_ECG 0;
BA_ "GenSigTimeoutTime_HCM_SUBNET" SG_ 2611175503 PARSEDPhysLDCMAtoGWM_ECG 0;
BA_ "GenSigSendType" SG_ 2611175503 PARSEDPhysLDCMAtoGWM_ECG 3;
BA_ "GenSigTimeoutTime_X_LDMFL1" SG_ 2612002008 PARSEDFuncGWM_ECG 0;
BA_ "GenSigTimeoutTime_X_LDMFR1" SG_ 2612002008 PARSEDFuncGWM_ECG 0;
BA_ "GenSigTimeoutTime_HCM_SUBNET" SG_ 2612002008 PARSEDFuncGWM_ECG 0;
BA_ "GenSigSendType" SG_ 2612002008 PARSEDFuncGWM_ECG 3;
BA_ "GenSigTimeoutTime_X_LDMFL1" SG_ 2610126927 OTAPhysLDCMAtoGWM_ECG 0;
BA_ "GenSigTimeoutTime_X_LDMFR1" SG_ 2610126927 OTAPhysLDCMAtoGWM_ECG 0;
BA_ "GenSigTimeoutTime_HCM_SUBNET" SG_ 2610126927 OTAPhysLDCMAtoGWM_ECG 0;
BA_ "GenSigSendType" SG_ 2610126927 OTAPhysLDCMAtoGWM_ECG 3;
BA_ "GenSigTimeoutTime_X_LDMFL1" SG_ 2609986776 OTAPhysGWM_ECGtoLDCMA 0;
BA_ "GenSigTimeoutTime_X_LDMFR1" SG_ 2609986776 OTAPhysGWM_ECGtoLDCMA 0;
BA_ "GenSigTimeoutTime_HCM_SUBNET" SG_ 2609986776 OTAPhysGWM_ECGtoLDCMA 0;
BA_ "GenSigSendType" SG_ 2609986776 OTAPhysGWM_ECGtoLDCMA 3;
BA_ "GenSigTimeoutTime_X_LDMFL1" SG_ 2610953432 OTAFuncGWM_ECG 0;
BA_ "GenSigTimeoutTime_X_LDMFR1" SG_ 2610953432 OTAFuncGWM_ECG 0;
BA_ "GenSigTimeoutTime_HCM_SUBNET" SG_ 2610953432 OTAFuncGWM_ECG 0;
BA_ "GenSigSendType" SG_ 2610953432 OTAFuncGWM_ECG 3;
BA_ "U_U611_U625_MY20_Phev_Tx" SG_ 80 ExtLghtAnmtn_D_Rq 1;
BA_ "GenSigSendType" SG_ 80 ExtLghtAnmtn_D_Rq 3;
BA_ "GenSigStartValue" SG_ 80 ExtLghtAnmtn_D_Rq 1;
BA_ "GenSigStartValue" SG_ 80 HeadLghtSwtch_D_Stat 3;
BA_ "GenSigSendType" SG_ 80 HeadLghtSwtch_D_Stat 3;
BA_ "GenSigSendType" SG_ 80 DrlPos4_Actv_Rf_Rq 3;
BA_ "GenSigSendType" SG_ 80 DrlPos4_Actv_Lf_Rq 3;
BA_ "GenSigSendType" SG_ 80 DrlPos3_Actv_Rf_Rq 3;
BA_ "U_U611_U625_MY20_Phev_Tx" SG_ 80 ExtLghtFront_D_RqBody 1;
BA_ "GenSigSendType" SG_ 80 ExtLghtFront_D_RqBody 3;
BA_ "GenSigStartValue" SG_ 80 ExtLghtFront_D_RqBody 1;
BA_ "GenSigSendType" SG_ 80 Front_Fog_Actv_Rq 3;
BA_ "GenSigSendType" SG_ 80 WfSubstate_D_Stat 3;
BA_ "GenSigSendType" SG_ 80 WfSuperstate_D_Stat 3;
BA_ "GenSigSendType" SG_ 80 Drl_Pos_Actv_Fade_Rf_Rq 3;
BA_ "GenSigSendType" SG_ 80 SideMarker_Actv_Rq 3;
BA_ "GenSigSendType" SG_ 80 Drl_Pos_Actv_Fade_Lf_Rq 3;
BA_ "GenSigSendType" SG_ 80 DrlPos2_Actv_Rf_Rq 3;
BA_ "GenSigSendType" SG_ 80 DrlPos1_Actv_Rf_Rq 3;
BA_ "GenSigSendType" SG_ 80 DrlPos2_Actv_Lf_Rq 3;
BA_ "GenSigSendType" SG_ 80 DrlPos1_Actv_Lf_Rq 3;
BA_ "GenSigSendType" SG_ 2015 TesterFunctionalReq 3;
BA_ "GenSigSendType" SG_ 1791 TesterPhysicalResLDCMB 3;
BA_ "GenSigSendType" SG_ 1790 TesterPhysicalResLDCMA 3;
BA_ "GenSigSendType" SG_ 1783 TesterPhysicalReqLDCMB 3;
BA_ "GenSigSendType" SG_ 1782 TesterPhysicalReqLDCMA 3;
BA_ "GenSigSendType" SG_ 1823 TesterPhysicalResLDCMF 3;
BA_ "GenSigSendType" SG_ 1822 TesterPhysicalResLDCME 3;
BA_ "GenSigSendType" SG_ 1815 TesterPhysicalReqLDCMF 3;
BA_ "GenSigSendType" SG_ 1814 TesterPhysicalReqLDCME 3;
BA_ "U_U611_U625_MY20_Phev_Tx" SG_ 117 Hlr_Temp_Stat 1;
BA_ "U_U611_U625_MY20_Phev_Tx" SG_ 117 Mdule1RightHl_side_Stat 1;
BA_ "U_U611_U625_MY20_Phev_Tx" SG_ 117 Mdule1RightHl_Com_Stat 1;
BA_ "U_U611_U625_MY20_Phev_Tx" SG_ 117 Mdule1Right_MPwr_B_Stat 1;
BA_ "U_U611_U625_MY20_Phev_Tx" SG_ 117 Mdule1Right_LB_Pwr_B_Stat 1;
BA_ "U_U611_U625_MY20_Phev_Tx" SG_ 117 Hlr_SM_Stat 1;
BA_ "U_U611_U625_MY20_Phev_Tx" SG_ 117 Hlr_SBL_Stat 1;
BA_ "U_U611_U625_MY20_Phev_Tx" SG_ 117 Hlr_Pixel_Stat 1;
BA_ "U_U611_U625_MY20_Phev_Tx" SG_ 117 Hlr_Fan_B_Stat 1;
BA_ "U_U611_U625_MY20_Phev_Tx" SG_ 117 Hlr_DRL_POS_Stat 1;
BA_ "U_U611_U625_MY20_Phev_Tx" SG_ 117 HeadLghtLvlRght_D_Stat 1;
BA_ "GenSigStartValue" SG_ 117 HeadLghtLvlRght_D_Stat 1;
BA_ "U_U611_U625_MY20_Phev_Tx" SG_ 117 HeadLghtLvlRght_No_Stat 1;
BA_ "U_U611_U625_MY20_Phev_Tx" SG_ 117 Mdule1RightFail_B_Stat 1;
BA_ "U_U611_U625_MY20_Phev_Tx" SG_ 117 Mdule1RightConfg_B_Stat 1;
BA_ "U_U611_U625_MY20_Phev_Tx" SG_ 116 HeadLghtLvlLeft_No_Stat 1;
BA_ "U_U611_U625_MY20_Phev_Tx" SG_ 116 Hll_Temp_Stat 1;
BA_ "U_U611_U625_MY20_Phev_Tx" SG_ 116 Mdule1LeftHl_side_Stat 1;
BA_ "U_U611_U625_MY20_Phev_Tx" SG_ 116 Mdule1LeftHl_Com_Stat 1;
BA_ "U_U611_U625_MY20_Phev_Tx" SG_ 116 Mdule1Left_MPwr_B_Stat 1;
BA_ "U_U611_U625_MY20_Phev_Tx" SG_ 116 Mdule1Left_LB_Pwr_B_Stat 1;
BA_ "U_U611_U625_MY20_Phev_Tx" SG_ 116 Hll_SM_Stat 1;
BA_ "U_U611_U625_MY20_Phev_Tx" SG_ 116 Hll_SBL_Stat 1;
BA_ "U_U611_U625_MY20_Phev_Tx" SG_ 116 Hll_Pixel_Stat 1;
BA_ "U_U611_U625_MY20_Phev_Tx" SG_ 116 Hll_Fan_B_Stat 1;
BA_ "U_U611_U625_MY20_Phev_Tx" SG_ 116 Hll_DRL_POS_Stat 1;
BA_ "U_U611_U625_MY20_Phev_Tx" SG_ 116 HeadLghtLvlLeft_D_Stat 1;
BA_ "GenSigStartValue" SG_ 116 HeadLghtLvlLeft_D_Stat 1;
BA_ "U_U611_U625_MY20_Phev_Tx" SG_ 116 Mdule1LeftFail_B_Stat 1;
BA_ "U_U611_U625_MY20_Phev_Tx" SG_ 116 Mdule1LeftConfg_B_Stat 1;
BA_ "U_U611_U625_MY20_Phev_Tx" SG_ 118 HeadLghtLvlRghtRef_D_Rq 1;
BA_ "U_U611_U625_MY20_Phev_Tx" SG_ 118 HeadLghtLvlLeftRef_D_Rq 1;
BA_ "U_U611_U625_MY20_Phev_Tx" SG_ 118 HeadLghtLvlRight_No_Rq 1;
BA_ "U_U611_U625_MY20_Phev_Tx" SG_ 118 HeadLghtLvlLeft_No_Rq 1;
BA_ "GenSigSendType" SG_ 85 HCMSleepyTime_B_Stat 3;
BA_ "U_U611_U625_MY20_Phev_Tx" SG_ 85 HCMSleepyTime_B_Stat 1;
BA_ "U_U611_U625_MY20_Phev_Tx" SG_ 85 Ignition_Status 1;
BA_ "GenSigSendType" SG_ 85 Ignition_Status 3;
BA_ "GenSigStartValue" SG_ 85 Ignition_Status 1;
BA_ "U_U611_U625_MY20_Phev_Tx" SG_ 85 PwPckTq_D_Stat 1;
BA_ "GenSigSendType" SG_ 85 PwPckTq_D_Stat 3;
BA_ "U_U611_U625_MY20_Phev_Tx" SG_ 85 ElPw_D_Stat 1;
BA_ "GenSigSendType" SG_ 85 ElPw_D_Stat 3;
BA_ "GenSigStartValue" SG_ 85 GearLvrPos_D_Actl 14;
BA_ "U_U611_U625_MY20_Phev_Tx" SG_ 98 Traffic_Style_Rq 1;
BA_ "U_U611_U625_MY20_Phev_Tx" SG_ 98 SwvlTrgtLeft_An_Rq 1;
BA_ "GenSigStartValue" SG_ 98 SwvlTrgtLeft_An_Rq 875;
BA_ "U_U611_U625_MY20_Phev_Tx" SG_ 98 SwvlTrgtRight_An_Rq 1;
BA_ "GenSigStartValue" SG_ 98 SwvlTrgtRight_An_Rq 875;
BA_ "U_U611_U625_MY20_Phev_Tx" SG_ 98 LowBeamLightClassL_T_Rq 1;
BA_ "U_U611_U625_MY20_Phev_Tx" SG_ 98 LowBeamLightClassR_T_Rq 1;
BA_ "U_U611_U625_MY20_Phev_Tx" SG_ 98 LowBeamLightClassL_D_Rq 1;
BA_ "U_U611_U625_MY20_Phev_Tx" SG_ 98 LowBeamLightClassR_D_Rq 1;
BA_ "U_U611_U625_MY20_Phev_Tx" SG_ 113 Slght5VRight_T_Rq 1;
BA_ "U_U611_U625_MY20_Phev_Tx" SG_ 113 Slght5BrghtRight_Pc_Rq 1;
BA_ "U_U611_U625_MY20_Phev_Tx" SG_ 113 Slght4VRight_T_Rq 1;
BA_ "U_U611_U625_MY20_Phev_Tx" SG_ 113 Slght4BrghtRight_Pc_Rq 1;
BA_ "U_U611_U625_MY20_Phev_Tx" SG_ 113 Slght3VRight_T_Rq 1;
BA_ "U_U611_U625_MY20_Phev_Tx" SG_ 113 Slght3BrghtRight_Pc_Rq 1;
BA_ "U_U611_U625_MY20_Phev_Tx" SG_ 113 Slght2VRight_T_Rq 1;
BA_ "U_U611_U625_MY20_Phev_Tx" SG_ 113 Slght2BrghtRight_Pc_Rq 1;
BA_ "U_U611_U625_MY20_Phev_Tx" SG_ 113 Slght1VRight_T_Rq 1;
BA_ "U_U611_U625_MY20_Phev_Tx" SG_ 113 Slght1BrghtRight_Pc_Rq 1;
BA_ "U_U611_U625_MY20_Phev_Tx" SG_ 112 Slght5VLeft_T_Rq 1;
BA_ "U_U611_U625_MY20_Phev_Tx" SG_ 112 Slght5BrghtLeft_Pc_Rq 1;
BA_ "U_U611_U625_MY20_Phev_Tx" SG_ 112 Slght4VLeft_T_Rq 1;
BA_ "U_U611_U625_MY20_Phev_Tx" SG_ 112 Slght4BrghtLeft_Pc_Rq 1;
BA_ "U_U611_U625_MY20_Phev_Tx" SG_ 112 Slght3VLeft_T_Rq 1;
BA_ "U_U611_U625_MY20_Phev_Tx" SG_ 112 Slght3BrghtLeft_Pc_Rq 1;
BA_ "U_U611_U625_MY20_Phev_Tx" SG_ 112 Slght2VLeft_T_Rq 1;
BA_ "U_U611_U625_MY20_Phev_Tx" SG_ 112 Slght2BrghtLeft_Pc_Rq 1;
BA_ "U_U611_U625_MY20_Phev_Tx" SG_ 112 Slght1VLeft_T_Rq 1;
BA_ "U_U611_U625_MY20_Phev_Tx" SG_ 112 Slght1BrghtLeft_Pc_Rq 1;
BA_ "WakeupSignal" SG_ 2147484595 DrStatRl_B_Actl 1;
BA_ "GenSigSendType" SG_ 2147484595 DrStatRl_B_Actl 3;
BA_ "WakeupSignal" SG_ 2147484595 DrStatRr_B_Actl 1;
BA_ "GenSigSendType" SG_ 2147484595 DrStatRr_B_Actl 3;
BA_ "WakeupSignal" SG_ 2147484595 DrStatInnrTgate_B_Actl 1;
BA_ "GenSigSendType" SG_ 2147484595 DrStatInnrTgate_B_Actl 3;
BA_ "WakeupSignal" SG_ 2147484595 DrStatPsngr_B_Actl 1;
BA_ "GenSigSendType" SG_ 2147484595 DrStatPsngr_B_Actl 3;
BA_ "WakeupSignal" SG_ 2147484595 DrStatDrv_B_Actl 1;
BA_ "GenSigSendType" SG_ 2147484595 DrStatDrv_B_Actl 3;
VAL_ 785 TurnLampFrOut_B_Stat2 1 "Out" 0 "Null" ;
VAL_ 785 HeadLampLoFrOut_B_Stat2 1 "Faulted" 0 "NotFaulted" ;
VAL_ 769 TurnLampFlOut_B_Stat2 1 "Out" 0 "Null" ;
VAL_ 769 HeadLampLoFlOut_B_Stat2 1 "Faulted" 0 "NotFaulted" ;
VAL_ 125 LDM_HbFdbckRght_B_Stat2 1 "At least one activated" 0 "All deactivated" ;
VAL_ 125 HlLoFrOnfdbck_B_Stat2 1 "Low" 0 "Not_Low" ;
VAL_ 125 Hlr_Temp_Stat2 1 "HL over temperature " 0 "HL temperature OK" ;
VAL_ 125 Mdule2RightHl_side_Stat 2 "LDM side detection failed." 1 "LDM detected right side." 0 "LDM detected left side." ;
VAL_ 125 Mdule2RightHl_Com_Stat 1 "Physical CAN bus com lost" 0 "Physical CAN bus OK" ;
VAL_ 125 Mdule2Right_MPwr_B_Stat 1 "LDM main power supply power lost" 0 "LDM main power supply available." ;
VAL_ 125 Mdule2Right_LB_Pwr_B_Stat 1 "LDM LB power supply power lost" 0 "LDM LB power supply available" ;
VAL_ 125 Hlr_SM_Stat2 1 "SM unit failure detected" 0 "SM unit status OK" ;
VAL_ 125 Hlr_SBL_Stat2 1 "SBL unit failure detected" 0 "SBL unit status OK" ;
VAL_ 125 Hlr_Pixel_Stat2 1 "Pixel unit failure detected" 0 "Pixel unit status OK" ;
VAL_ 125 Hlr_Fan_B_Stat2 1 "Fan failure detected" 0 "Fan status OK" ;
VAL_ 125 Hlr_DRL_POS_Stat2 1 "DRL_POS unit failure detected" 0 "DRL_POS unit status OK" ;
VAL_ 125 Hlr_LvlMotor_Temp_Stat2 2 "Overtemperature" 1 "High Temperature" 0 "Status OK" ;
VAL_ 125 HeadLghtLvlRght_D_Stat2 2 "System_OK" 3 "Ref ongoing" 1 "Ref required" 0 "FAULT" ;
VAL_ 125 HeadLghtLvlRght_No_Stat2 4095 "Faulty" ;
VAL_ 125 Mdule2RightFail_B_Stat 1 "LDM is NOK" 0 "LDM is OK" ;
VAL_ 125 Mdule2RightConfg_B_Stat 1 "FAULTY" 0 "OK" ;
VAL_ 124 LDM_HbFdbckLeft_B_Stat2 1 "At least one activated" 0 "All deactivated" ;
VAL_ 124 HlLoFlOnfdbck_B_Stat2 1 "Low" 0 "Not_Low" ;
VAL_ 124 HeadLghtLvlLeft_No_Stat2 4095 "Faulty" ;
VAL_ 124 Hll_Temp_Stat2 1 "HL over temperature " 0 "HL temperature OK" ;
VAL_ 124 Mdule2LeftHl_side_Stat 2 "LDM side detection failed." 1 "LDM detected right side." 0 "LDM detected left side." ;
VAL_ 124 Mdule2LeftHl_Com_Stat 1 "Physical CAN bus com lost" 0 "Physical CAN bus OK" ;
VAL_ 124 Mdule2Left_MPwr_B_Stat 1 "LDM main power supply power lost" 0 "LDM main power supply available." ;
VAL_ 124 Mdule2Left_LB_Pwr_B_Stat 1 "LDM LB power supply power lost" 0 "LDM LB power supply available" ;
VAL_ 124 Hll_SM_Stat2 1 "SM unit failure detected" 0 "SM unit status OK" ;
VAL_ 124 Hll_SBL_Stat2 1 "SBL unit failure detected" 0 "SBL unit status OK" ;
VAL_ 124 Hll_Pixel_Stat2 1 "Pixel unit failure detected" 0 "Pixel unit status OK" ;
VAL_ 124 Hll_Fan_B_Stat2 1 "Fan failure detected" 0 "Fan status OK" ;
VAL_ 124 Hll_DRL_POS_Stat2 1 "DRL_POS unit failure detected" 0 "DRL_POS unit status OK" ;
VAL_ 124 Hll_LvlMotor_Temp_Stat2 2 "Overtemperature" 1 "High Temperature" 0 "Status OK" ;
VAL_ 124 HeadLghtLvlLeft_D_Stat2 2 "System_OK" 3 "Ref ongoing" 1 "Ref required" 0 "FAULT" ;
VAL_ 124 Mdule2LeftFail_B_Stat 1 "LDM is NOK" 0 "LDM is OK" ;
VAL_ 124 Mdule2LeftConfg_B_Stat 1 "FAULTY" 0 "OK" ;
VAL_ 123 TailLghtAnmtnRight_D_Stat 15 "Faulty" 14 "NotUsed_7" 13 "NotUsed_6" 12 "NotUsed_5" 11 "NotUsed_4" 10 "NotUsed_3" 9 "NotUsed_2" 8 "NotUsed_1" 7 "Type7" 6 "Type6" 5 "Type5" 4 "Type4" 3 "Type3" 2 "Type2" 1 "Type1" 0 "Null" ;
VAL_ 122 TailLghtAnmtnLeft_D_Stat 15 "Faulty" 14 "NotUsed_7" 13 "NotUsed_6" 12 "NotUsed_5" 11 "NotUsed_4" 10 "NotUsed_3" 9 "NotUsed_2" 8 "NotUsed_1" 7 "Type7" 6 "Type6" 5 "Type5" 4 "Type4" 3 "Type3" 2 "Type2" 1 "Type1" 0 "Null" ;
VAL_ 102 Hbm6Mde_D_Rq 15 "NotUsed_13" 14 "NotUsed_12" 13 "NotUsed_11" 12 "NotUsed_10" 11 "NotUsed_9" 10 "NotUsed_8" 9 "NotUsed_7" 8 "NotUsed_6" 7 "NotUsed_5" 6 "NotUsed_4" 5 "NotUsed_3" 4 "NotUsed_2" 3 "NotUsed_1" 2 "TrafficSignDeGlare" 1 "DarkSpot" 0 "None" ;
VAL_ 102 Hbm5Mde_D_Rq 15 "NotUsed_13" 14 "NotUsed_12" 13 "NotUsed_11" 12 "NotUsed_10" 11 "NotUsed_9" 10 "NotUsed_8" 9 "NotUsed_7" 8 "NotUsed_6" 7 "NotUsed_5" 6 "NotUsed_4" 5 "NotUsed_3" 4 "NotUsed_2" 3 "NotUsed_1" 2 "TrafficSignDeGlare" 1 "DarkSpot" 0 "None" ;
VAL_ 102 Hbm4Mde_D_Rq 15 "NotUsed_13" 14 "NotUsed_12" 13 "NotUsed_11" 12 "NotUsed_10" 11 "NotUsed_9" 10 "NotUsed_8" 9 "NotUsed_7" 8 "NotUsed_6" 7 "NotUsed_5" 6 "NotUsed_4" 5 "NotUsed_3" 4 "NotUsed_2" 3 "NotUsed_1" 2 "TrafficSignDeGlare" 1 "DarkSpot" 0 "None" ;
VAL_ 102 Hbm3Mde_D_Rq 15 "NotUsed_13" 14 "NotUsed_12" 13 "NotUsed_11" 12 "NotUsed_10" 11 "NotUsed_9" 10 "NotUsed_8" 9 "NotUsed_7" 8 "NotUsed_6" 7 "NotUsed_5" 6 "NotUsed_4" 5 "NotUsed_3" 4 "NotUsed_2" 3 "NotUsed_1" 2 "TrafficSignDeGlare" 1 "DarkSpot" 0 "None" ;
VAL_ 102 Hbm2Mde_D_Rq 15 "NotUsed_13" 14 "NotUsed_12" 13 "NotUsed_11" 12 "NotUsed_10" 11 "NotUsed_9" 10 "NotUsed_8" 9 "NotUsed_7" 8 "NotUsed_6" 7 "NotUsed_5" 6 "NotUsed_4" 5 "NotUsed_3" 4 "NotUsed_2" 3 "NotUsed_1" 2 "TrafficSignDeGlare" 1 "DarkSpot" 0 "None" ;
VAL_ 102 Hbm1Mde_D_Rq 15 "NotUsed_13" 14 "NotUsed_12" 13 "NotUsed_11" 12 "NotUsed_10" 11 "NotUsed_9" 10 "NotUsed_8" 9 "NotUsed_7" 8 "NotUsed_6" 7 "NotUsed_5" 6 "NotUsed_4" 5 "NotUsed_3" 4 "NotUsed_2" 3 "NotUsed_1" 2 "TrafficSignDeGlare" 1 "DarkSpot" 0 "None" ;
VAL_ 102 HeadLghtHi_D_Rq 7 "NotUsed_4" 6 "NotUsed_3" 5 "NotUsed_2" 4 "NotUsed_1" 3 "OnAutomatic" 2 "OnManual" 1 "Flash" 0 "Off" ;
VAL_ 784 TurnLampFrOut_B_Stat 1 "Out" 0 "Null" ;
VAL_ 784 HeadLampLoFrOut_B_Stat 1 "Faulted" 0 "NotFaulted" ;
VAL_ 768 TurnLampFlOut_B_Stat 1 "Out" 0 "Null" ;
VAL_ 768 HeadLampLoFlOut_B_Stat 1 "Faulted" 0 "NotFaulted" ;
VAL_ 800 TurnLghtRight_D_Rq 3 "Seq" 2 "On" 1 "Off" 0 "Null" ;
VAL_ 800 TurnLghtLeft_D_Rq 3 "Seq" 2 "On" 1 "Off" 0 "Null" ;
VAL_ 800 HeadLampLoFrOn_B_Stat 1 "Low" 0 "Not_Low" ;
VAL_ 800 HeadLampLoFlOn_B_Stat 1 "Low" 0 "Not_Low" ;
VAL_ 121 Hlr_DblMotor_Volt_D_Stat 3 "Normal Voltage Mode" 2 "Overvoltage Mode" 1 "Undervoltage Mode" 0 "Low Voltage Mode" ;
VAL_ 121 DblMtrRight_Motion_B_Stat 1 "Motor Moving" 0 "Motor Not Moving" ;
VAL_ 121 SwvlTrgtRight_An_D_Stat 2047 "Faulty" ;
VAL_ 121 Hlr_DblMotor_Temp_Stat 2 "Overtemperature" 1 "High Temperature" 0 "Status OK" ;
VAL_ 121 HeadLghtDblRght_D_Stat 2 "System_OK" 3 "Referencing" 1 "RefRequired" 0 "FAULT" ;
VAL_ 120 Hll_DblMotor_Volt_D_Stat 3 "Normal Voltage Mode" 2 "Overvoltage Mode" 1 "Undervoltage Mode" 0 "Low Voltage Mode" ;
VAL_ 120 DblMtrLeft_Motion_B_Stat 1 "Motor Moving" 0 "Motor Not Moving" ;
VAL_ 120 SwvlTrgtLeft_An_D_Stat 2047 "Faulty" ;
VAL_ 120 Hll_DblMotor_Temp_Stat 2 "Overtemperature" 1 "High Temperature" 0 "Status OK" ;
VAL_ 120 HeadLghtDbllLeft_D_Stat 2 "System_OK" 3 "Referencing" 1 "Ref Required" 0 "FAULT" ;
VAL_ 119 HeadLghtDblRghtRef_D_Rq 1 "Dbl ref only" 0 "No referencing action" ;
VAL_ 119 HeadLghtDblLeftRef_D_Rq 1 "Dbl ref only" 0 "No referencing action" ;
VAL_ 119 MtrSwvlTrgtRight_An_Rq 2047 "Faulty" ;
VAL_ 119 MtrSwvlTrgtLeft_An_Rq 2047 "Faulty" ;
VAL_ 80 ExtLghtAnmtn_D_Rq 15 "Faulty" 14 "NotUsed_8" 13 "NotUsed_7" 12 "NotUsed_6" 11 "NotUsed_5" 10 "NotUsed_4" 9 "NotUsed_3" 8 "NotUsed_2" 7 "NotUsed_1" 6 "Type6" 5 "Type5" 4 "Type4" 3 "Type3" 2 "Type2" 1 "Type1" 0 "Null" ;
VAL_ 80 HeadLghtSwtch_D_Stat 3 "Autolamp" 2 "Headlamp" 1 "Parklamp" 0 "Off" ;
VAL_ 80 DrlPos4_Actv_Rf_Rq 2 "DRL intensity" 1 "POS intensity" 0 "OFF" ;
VAL_ 80 DrlPos4_Actv_Lf_Rq 2 "DRL intensity" 1 "POS intensity" 0 "OFF" ;
VAL_ 80 DrlPos3_Actv_Rf_Rq 2 "DRL intensity" 1 "POS intensity" 0 "OFF" ;
VAL_ 80 DrlPos3_Actv_Lf_Rq 2 "DRL intensity" 1 "POS intensity" 0 "OFF" ;
VAL_ 80 ExtLghtFront_D_RqBody 3 "NotUsed" 2 "ON" 1 "OFF" 0 "Null" ;
VAL_ 80 Front_Fog_Actv_Rq 1 "Front Fog ON" 0 "Front Fog OFF" ;
VAL_ 80 WfSubstate_D_Stat 7 "IlluminatedExit" 6 "CourtesyLightingDelayExt" 5 "CourtesyLightingExtended" 4 "CourtesyLightingDelayAll" 3 "CourtesyLightingAll" 2 "IlluminatedEntry" 1 "Approach" 0 "NULL" ;
VAL_ 80 WfSuperstate_D_Stat 3 "RunStart" 2 "Farewell" 1 "Welcome" 0 "Null" ;
VAL_ 80 SideMarker_Actv_Rq 1 "ON" 0 "OFF" ;
VAL_ 80 DrlPos2_Actv_Rf_Rq 2 "DRL intensity" 1 "POS intensity" 0 "OFF" ;
VAL_ 80 DrlPos1_Actv_Rf_Rq 2 "DRL intensity" 1 "POS intensity" 0 "OFF" ;
VAL_ 80 DrlPos2_Actv_Lf_Rq 2 "DRL intensity" 1 "POS intensity" 0 "OFF" ;
VAL_ 80 DrlPos1_Actv_Lf_Rq 2 "DRL intensity" 1 "POS intensity" 0 "OFF" ;
VAL_ 117 LDM_HbFdbckRght_B_Stat 1 "At least one activated" 0 "All deactivated" ;
VAL_ 117 HlLoFrOnfdbck_B_Stat 1 "Low" 0 "Not_Low" ;
VAL_ 117 Hlr_Temp_Stat 1 "HL over temperature " 0 "HL temperature OK" ;
VAL_ 117 Mdule1RightHl_side_Stat 2 "LDM side detection failed." 1 "LDM detected right side." 0 "LDM detected left side." ;
VAL_ 117 Mdule1RightHl_Com_Stat 1 "Physical CAN bus com lost" 0 "Physical CAN bus OK" ;
VAL_ 117 Mdule1Right_MPwr_B_Stat 1 "LDM main power supply power lost" 0 "LDM main power supply available." ;
VAL_ 117 Mdule1Right_LB_Pwr_B_Stat 1 "LDM LB power supply power lost" 0 "LDM LB power supply available" ;
VAL_ 117 Hlr_SM_Stat 1 "SM unit failure detected" 0 "SM unit status OK" ;
VAL_ 117 Hlr_SBL_Stat 1 "SBL unit failure detected" 0 "SBL unit status OK" ;
VAL_ 117 Hlr_Pixel_Stat 1 "Pixel unit failure detected" 0 "Pixel unit status OK" ;
VAL_ 117 Hlr_Fan_B_Stat 1 "Fan failure detected" 0 "Fan status OK" ;
VAL_ 117 Hlr_DRL_POS_Stat 1 "DRL_POS unit failure detected" 0 "DRL_POS unit status OK" ;
VAL_ 117 Hlr_LvlMotor_Temp_Stat 2 "Overtemperature" 1 "High Temperature" 0 "Status OK" ;
VAL_ 117 HeadLghtLvlRght_D_Stat 2 "System_OK" 3 "Ref ongoing" 1 "Ref required" 0 "FAULT" ;
VAL_ 117 HeadLghtLvlRght_No_Stat 4095 "Faulty" ;
VAL_ 117 Mdule1RightFail_B_Stat 1 "LDM is NOK" 0 "LDM is OK" ;
VAL_ 117 Mdule1RightConfg_B_Stat 1 "FAULTY" 0 "OK" ;
VAL_ 116 LDM_HbFdbckLeft_B_Stat 1 "At least one activated" 0 "All deactivated" ;
VAL_ 116 HlLoFlOnfdbck_B_Stat 1 "Low" 0 "Not_Low" ;
VAL_ 116 HeadLghtLvlLeft_No_Stat 4095 "Faulty" ;
VAL_ 116 Hll_Temp_Stat 1 "HL over temperature " 0 "HL temperature OK" ;
VAL_ 116 Mdule1LeftHl_side_Stat 2 "LDM side detection failed." 1 "LDM detected right side." 0 "LDM detected left side." ;
VAL_ 116 Mdule1LeftHl_Com_Stat 1 "Physical CAN bus com lost" 0 "Physical CAN bus OK" ;
VAL_ 116 Mdule1Left_MPwr_B_Stat 1 "LDM main power supply power lost" 0 "LDM main power supply available." ;
VAL_ 116 Mdule1Left_LB_Pwr_B_Stat 1 "LDM LB power supply power lost" 0 "LDM LB power supply available" ;
VAL_ 116 Hll_SM_Stat 1 "SM unit failure detected" 0 "SM unit status OK" ;
VAL_ 116 Hll_SBL_Stat 1 "SBL unit failure detected" 0 "SBL unit status OK" ;
VAL_ 116 Hll_Pixel_Stat 1 "Pixel unit failure detected" 0 "Pixel unit status OK" ;
VAL_ 116 Hll_Fan_B_Stat 1 "Fan failure detected" 0 "Fan status OK" ;
VAL_ 116 Hll_DRL_POS_Stat 1 "DRL_POS unit failure detected" 0 "DRL_POS unit status OK" ;
VAL_ 116 Hll_LvlMotor_Temp_Stat 2 "Overtemperature" 1 "High Temperature" 0 "Status OK" ;
VAL_ 116 HeadLghtLvlLeft_D_Stat 2 "System_OK" 3 "Ref ongoing" 1 "Ref required" 0 "FAULT" ;
VAL_ 116 Mdule1LeftFail_B_Stat 1 "LDM is NOK" 0 "LDM is OK" ;
VAL_ 116 Mdule1LeftConfg_B_Stat 1 "FAULTY" 0 "OK" ;
VAL_ 118 HeadLghtLvlRghtRef_D_Rq 5 "Start partially reference 4" 4 "Start partially reference 3" 3 "Start partially reference 2" 2 "Lvl ref only" 1 "Start full rerence" 0 "No referencing action" ;
VAL_ 118 HeadLghtLvlLeftRef_D_Rq 5 "Start partially reference 4" 4 "Start partially reference 3" 3 "Start partially reference 2" 2 "Lvl ref only" 1 "Start full rerence" 0 "No referencing action" ;
VAL_ 118 HeadLghtLvlRight_No_Rq 4095 "Faulty" ;
VAL_ 118 HeadLghtLvlLeft_No_Rq 4095 "Faulty" ;
VAL_ 85 HCMSleepyTime_B_Stat 1 "Sleep_imminent" 0 "Null" ;
VAL_ 85 Ignition_Status 15 "Invalid" 8 "Start" 4 "Run" 2 "Accessory" 1 "Off" 0 "Unknown" ;
VAL_ 85 PwPckTq_D_Stat 3 "PwPckOn_TqAvailable" 2 "PwPckStrtInProg_TqNotAvail" 1 "PwPckOn_TqNotAvailable" 0 "PwPckOff_TqNotAvailable" ;
VAL_ 85 ElPw_D_Stat 7 "NotUsed_3" 6 "NotUsed_2" 5 "NotUsed_1" 4 "Fault limited" 3 "LV event in progress" 2 "Not supported imminent" 1 "Supported" 0 "Not supported" ;
VAL_ 85 Eng_D_Stat 0 "EngOff" 1 "EngOn" 2 "EngAutoStopped" 3 "NotUsed" ;
VAL_ 85 GearLvrPos_D_Actl 0 "Park" 1 "Reverse" 2 "Neutral" 3 "Drive" 4 "Sport_DriveSport" 5 "Low" 6 "first" 7 "second" 8 "third" 9 "fourth" 10 "fifth" 11 "sixth" 12 "Undefined_Treat_as_Fault" 13 "Undefined_Treat_as__Fault" 14 "Unknown_Position" 15 "Fault" ;
VAL_ 98 Traffic_Style_Rq 1 "RHT" 0 "LHT" ;
VAL_ 98 SwvlTrgtLeft_An_Rq 2047 "Faulty" ;
VAL_ 98 SwvlTrgtRight_An_Rq 2047 "Faulty" ;
VAL_ 98 LowBeamLightClassL_D_Rq 13 "Class W" 12 "Class E3" 11 "Class E2" 10 "Class E1" 9 "Class E" 8 "Class C4" 7 "Class C3" 6 "Class C2" 5 "Class C1" 4 "Class V3" 3 "Class V2" 2 "Class V1" 1 "Class V" 0 "Class C" ;
VAL_ 98 LowBeamLightClassR_D_Rq 13 "Class W" 12 "Class E3" 11 "Class E2" 10 "Class E1" 9 "Class E" 8 "Class C4" 7 "Class C3" 6 "Class C2" 5 "Class C1" 4 "Class V3" 3 "Class V2" 2 "Class V1" 1 "Class V" 0 "Class C" ;
VAL_ 2147484595 DrStatRl_B_Actl 0 "Closed" 1 "Ajar" ;
VAL_ 2147484595 DrStatRr_B_Actl 0 "Closed" 1 "Ajar" ;
VAL_ 2147484595 DrStatInnrTgate_B_Actl 0 "Closed" 1 "Ajar" ;
VAL_ 2147484595 DrStatPsngr_B_Actl 0 "Closed" 1 "Ajar" ;
VAL_ 2147484595 DrStatDrv_B_Actl 0 "Closed" 1 "Ajar" ;
SIG_GROUP_ 800 Profile1A_320 1 : CanMsg320_No_Crc CanMsg320_No_Cnt TurnLghtRight_D_Rq TurnLghtLeft_D_Rq HeadLampLoFrOn_B_Stat HeadLampLoFlOn_B_Stat;
